VERSION "LiveWire S2 Del Mar (2024, S2DM) - Secondary CAN (DLC tap) - community reverse-engineered v0.1"
// [UPDATE 2026-07-27 — ride1 real-timestamp capture + deep review; double-verified.
//  0x181 IS THE FULL BMS MEASUREMENT FRAME: pack voltage + signed pack current.
//  RETRACTS the "~2.9-3 V/count", batt_flow_181, and the D3 "redundant-voltage" audit
//  below (every legacy observation re-explains as IR-drop on ONE voltage).]
//   pack_voltage = (D1:D2) >> 4 = 1 V/count (12-bit). Rest ~389 V @ 92% SoC; WOT dip
//     to 304 V then recover (ride1 393->304->393). D5 (pack_voltage_d5copy) is a
//     legacy 8-bit COPY = volts-256 (exact or off by <=2) - THIS is what the old
//     "~2.9-3 V/count" was mis-scaling; it is 1 V/count with a 256 offset.
//   pack_current = (D2&0x0F)<<12 | D3<<4 | D4>>4, then I = (raw-4000)/10 A, CHARGE-
//     POSITIVE. Zero-pinned: contactor-open raw=4000 (true 0 A) in 48/80 ignition
//     frames; DC-DC quiescent -0.2..-0.5 A at rest. WOT -189.5 A @ 304 V = 57.6 kW
//     (<63 kW rated). Charging +1.3..+3.9 A at 392-395 V ~ L1 wall power. D4 LOW
//     nibble = validity flag (0 co-occurs with raw==4000 in ~98-100% of open frames).
//   [CHARGE-POSITIVE RE-CONFIRMED 2026-07-28] The charge-positive sign is independently
//     re-confirmed by a sustained external charge (s32-s35: 100% positive pack_i with
//     monotonically rising V/SoC/cells), cross-checked vs UDS RESS 0209 pack current.
//   OHMIC CROSS-CHECK: V = 387.5 - 0.438*I, r=0.9947, rms 1.57 V, n=169 (~4.6 mohm/
//     cell at 96S); slope reproduces cross-capture. Independently cross-validated by
//     the 0x186 Wh meter integral (see 0x186). Continuous pack current/power IS on
//     secondary - RETRACTS the project's "pack current absent" gap.
//   ABSOLUTE 0.1 A/count rests on the wall-wattage match -> pin with an L2 (~5 kW)
//     charge (should read +12..13 A, raw ~4120-4130).
//   (D6 still 0x00 unused. The old counterexamples - "75mph"/manual-spin high current
//    at rest - resolve as unloaded STAND spins, ~-15 A at wheel inertia.)
// --- SUPERSEDED HISTORICAL DECODE (kept as the research record; do NOT wire) ------
// [STRONG] 0x181 D5 = PACK (HV BATTERY) VOLTAGE.
//   FOUND BY SYSTEMATIC TIMELINE CORRELATION (rider's suggestion): correlating every
//   raw byte against every confirmed signal across 6 dynamic captures surfaced
//   0x181 D5 at r=+0.80 vs battery flow - it had been sitting unexplained for the
//   whole project.
//   EVIDENCE IT IS VOLTAGE rather than another power field:
//     1. RESTING VALUE TRACKS SoC MONOTONICALLY across 47 captures:
//          SoC  96% -> 135       SoC  99% -> 136
//          SoC  97% -> 135/136   SoC 100% -> 137  (test.csv 138)
//          SoC  98% -> 135/136
//        Only an open-circuit voltage behaves like this - a power or current field
//        reads the same at rest regardless of SoC.
//     2. SAGS UNDER LOAD: falls to 127 during hard acceleration.
//     3. RISES WHEN CHARGING: 138-139 charging, 139 peak on regen.
//   SCALE: ~2.9-3 V PER COUNT, i.e. a ~400 V pack. RESOLVED BY PHYSICAL MEASUREMENT.
//     The rider measured the HV pack-to-inverter cable at 10 mm OD including
//     insulation. With typical HV wall thickness that implies roughly a 16 mm^2
//     conductor, good for ~110-150 A. At 63 kW peak that demands a HIGH-voltage
//     pack (~400 V, ~160 A). A 136 V pack would need ~460 A, requiring 50-70 mm^2
//     and a 15-20 mm OD - twice what was measured. So raw = volts is WRONG.
//     136 counts x ~2.9 V = ~394 V, which at ~96 series cells is 4.1 V/cell at full
//     charge - exactly as sensible as the 33s arithmetic below.
//   *** RETRACTED: "raw = volts, ~136 V pack, ~33s". The cell-voltage arithmetic
//     that supported it is WORTHLESS AS EVIDENCE because it works equally well for
//     BOTH hypotheses (33 cells at 1 V/count and 96 cells at ~2.9 V/count both give
//     ~4.1 V/cell). It only looked convincing because the alternative was never
//     checked. Lesson: internal consistency of a scaling assumption is not evidence
//     unless the competing assumption fails it.
//   *** ALSO RETRACTED: the "no DC fast charging implies a sub-threshold pack"
//     argument. At ~400 V the S2 is comfortably above any DCFC minimum, so the
//     omission is a cost / packaging / thermal decision, not physics.
//   REMAINING UNCERTAINTY: the exact counts-per-volt (2.9? 3.0?) is not pinned - the
//     cable gauge fixes the ORDER OF MAGNITUDE, not the precise scale.
//   DEFINITIVE TEST: a UDS read of the RESS returning pack voltage in known units.
// [STRONG] 0x181 D2:D3 (16-bit) = another battery flow / current-like channel.
//   r = +0.874 vs battery flow, -0.732 vs motor load. Rest 33017, charging 45307,
//   ride 241..61681. Bidirectional about rest with discharge swinging ~3x further
//   than regen, consistent with drive-vs-regen asymmetry. Resolution (30 distinct
//   values in a ride) is comparable to existing flow fields, not better - so it is
//   NOT the "true continuous" battery power still being sought.
// FULL FRAME MAP for 0x181 (audited byte by byte):
//   D1 = 23-24, essentially constant. Header / status. No information yet.
//   D2 = battery-flow-like, QUANTISED to multiples of 16 (0..240). r=+0.87 vs
//        battery flow, -0.73 vs motor load. Another stepped flow copy, not finer.
//   D3 = REDUNDANT PACK-VOLTAGE MEASUREMENT (hypothesis, well supported).
//        r=+0.977 vs D5, same 13 distinct values, band 236-252, same direction
//        (falls under load, rises charging), and sags by nearly the same ABSOLUTE
//        amount as D5 (6 vs 7 counts) - i.e. same scale.
//        KEY EVIDENCE: D3 - D5 is tightly clustered at 113 but NOT constant - it
//        spans 111..115 (113 = 51 %, 112 = 21 %, 114 = 17 %, 111 = 11 %). If D3 were
//        derived arithmetically from D5 the difference would be EXACTLY fixed. The
//        +/-2 count jitter means these are TWO INDEPENDENT MEASUREMENTS of the same
//        quantity, sharing a scale but using a different encoding offset.
//        WHY A SYSTEM WOULD DO THIS: safety-critical HV packs measure voltage on two
//        separate sense paths and cross-check them. Deliberately DIFFERENT offsets
//        mean a stuck bit or failed ADC cannot produce two matching plausible values
//        - any disagreement beyond a threshold flags a sensor fault. The +/-2 counts
//        is the expected noise between two ADC chains.
//        RULED OUT: D3 as MINIMUM CELL VOLTAGE. A weakest-cell reading must sag
//        proportionally HARDER than the pack under load; D3 sags 2.6 % against the
//        pack's 5.2 %, i.e. LESS. Not a cell-level metric.
//   D4 = shared STATUS byte (0xD1<->0xE1 tracks kickstand, but it also moves during
//        signal tests). Do NOT pair D3:D4 as a 16-bit value - although that pairing
//        correlates r=+0.985 with pack voltage and shows 77 distinct values, the
//        SPREAD WITHIN a single D5 step (up to 496) exceeds the step size (~238),
//        i.e. the extra "resolution" is D4's status bits leaking in, not real
//        precision. A tempting false lead.
//   D5 = PACK VOLTAGE (see above).
//   D6 = always 0x00 in every capture. Unused.
//   WHAT ITS CONSUMERS NEED (reasoning from the three secondary-bus receivers -
//   the IM/dash, the TCU/app, and the DLC - since the RESS itself is on primary,
//   everything gatewayed here serves a DISPLAY, an APP or a DIAGNOSTIC, never a
//   control loop):
//     satisfied here  -> pack voltage (the dash Diagnostics page shows voltages),
//                        battery flow (app power display), redundancy cross-check
//     satisfied elsewhere -> SoC (0x185), charge state (0x1A7), temps (0x183)
//     STILL UNLOCATED, and worth hunting because a dash/app plausibly needs them:
//       * BATTERY WARNING / FAULT flags (over-voltage, under-voltage, over-temp).
//         Likely a bitfield; look for a byte that is 0 in all healthy captures.
//       * STATE OF HEALTH (SoH). Would be near-constant across every capture and
//         change only over months - effectively invisible in this dataset. A byte
//         sitting at a fixed high value (e.g. ~100, ~200, ~255) is a candidate.
//       * AVAILABLE POWER LIMIT (discharge/charge ceilings the BMS computes from
//         SoC and temperature). Would move with temperature and SoC but NOT with
//         instantaneous load - a distinctive signature worth testing when the pack
//         is cold vs hot.
//       * TIME-TO-FULL while charging - would count DOWN during a charge session.
//   CONCLUSION: this frame contains NO continuous absolute power value. Its flow
//   channels (D2) are stepped like all the others.
// ---- 0x260 (608) : mode mirror ----------------------------------------------
BO_ 608 MODE_MIRROR_260: 8 Vector__XXX
 SG_ ride_mode_mirror : 7|8@0+ (1,0) [0|255] "" Vector__XXX
 SG_ ride_mode_mirror_d2 : 15|8@0+ (1,0) [0|255] "" Vector__XXX

// [CONFIRMED] 0x260 D1 mirrors 0x134 D1 ride-mode enum exactly
//   (22->88->99->33->44->11->22 through the mode cycle).
// [CONFIRMED] 0x260 D2 high-nibble = mode id too (20/10/40/30/80/90 for
//   Sport/Street/Eco/Rain/CustA/CustB); low nibble 0. See the 0x134 mode table.
// ---- 0x562 (1378) : ODOMETER ------------------------------------------------
BO_ 1378 ODOMETER_562: 8 IM
 SG_ odometer_m : 15|24@0+ (1,0) [0|16777215] "m" Vector__XXX
 SG_ msg_counter_562 : 55|8@0+ (1,0) [0|63] "" Vector__XXX

// [CONFIRMED] 0x562 D2:D3:D4 (24-bit big-endian) = odometer in METERS.
//   0x3DA4B5 = 4039861 m = 4039.86 km = 2510.26 mi  vs dash 2510 mi. Exact.
//   Verified again on 75mph run: 4039947m (2510.31mi) start, accumulated with
//   wheel travel. 0x3C6 D2:D3:D4 mirrors the same odometer (D6=0x30 constant).
//   D7 = rolling counter (0-63), D8 = checksum (ignore).
//   [UPDATE 2026-07-27] Confirmed with real timestamps: 0x3C6 D2:D3:D4 is an
//   unprotected ECHO of this odometer, lagging a median 214 ms (0/69 leads). This
//   DISSOLVES the ride1 "0x3C6 D4 ramp 0x61->0x71" candidate - it is just the
//   odometer low byte advancing. (0x562 itself integrates the REAR/motor-derived
//   speed: it over-counts under wheelspin and advances during stand spins - +223 m
//   logged in the 75mph stand capture with the front wheel static.)
// ---- 0x354 (852) : left switchgear - horn + info/scroll button --------------
BO_ 852 LEFT_SWITCH_354: 8 BCM
 SG_ horn : 15|8@0+ (1,0) [0|255] "" Vector__XXX
 SG_ info_scroll_button : 7|8@0+ (1,0) [0|255] "" Vector__XXX

// [STRONG] 0x354 D1 = dash INFO / SCROLL button (left cluster): 0x00 released,
//   0x01 pressed. Isolated in tripA71to0tripB70p9to0: pulsed ~3x while navigating the
//   dash menu to reset Trip A then Trip B. It is 0x00 with ZERO changes in every
//   control capture (idle, cyclemodes, highbeam, AND horn3x - where D2/horn pulses but
//   D1 stays flat), so it is a distinct button, not horn bleed. Same frame as the
//   horn = left switchgear. Exact button label (info vs mode) is [STRONG] not proven,
//   but it is the dash-navigation button used for trip reset / display cycling.
// [CONFIRMED] 0x354 D2 = horn: 0x00 released -> 0x01 pressed.
//   Verified with horn3x_fast capture: pulses EXACTLY 3x matching 3 honks, AND
//   reads 0x00 in every non-horn capture (idle, ignition, highbeam, turn signal).
//   NOTE: a single 1s press was inconclusive (one pulse indistinguishable from
//   idle jitter; several noise bytes looked like false candidates). The 3x-fast
//   capture was required to isolate it - the repeating 3-pulse signature plus
//   cross-check against non-horn captures eliminated all impostors.
//   (Earlier tentative "horn = analog" conclusion was WRONG - corrected here.)
// ---- 0x326 (806) : PER-WHEEL SPEEDS (front + rear, ABS sensors) -------------
BO_ 806 WHEEL_SPEEDS_326: 8 Vector__XXX
 SG_ wheel_speed_front : 7|16@0+ (0.1,0) [0|6553.5] "km/h" Vector__XXX
 SG_ wheel_speed_rear  : 23|16@0+ (0.1,0) [0|6553.5] "km/h" Vector__XXX

// [CONFIRMED] 0x326 D1:D2 = FRONT wheel speed, D3:D4 = REAR wheel speed.
//   Both 16-bit big-endian, same scale as vehicle_speed (km/h x10). Rest/zero
//   value is 2 (not 0) for both.
//   ISOLATION (definitive - the two halves of the dataset):
//     FRONT-only hand spin  -> D1:D2 = 2..48 ALIVE,  D3:D4 = 2 static
//     ALL rear-only spins   -> D1:D2 = 2 static,     D3:D4 tracks motion
//     idle (neither moving) -> both = 2
//   Scale cross-check vs 0x160 vehicle_speed: rear D3:D4 = 160 when speed = 161
//   (10 mph run) and 1245 vs 1248 (75 mph run). Same units.
//   NOTE: every capture before frontspin_5s had the front wheel STATIONARY, which
//   is why D1:D2 looked like a dead byte until the dedicated front-spin capture.
//   [CONFIRMED] FRONT wheel speed is UNSIGNED - spinning the front wheel BACKWARD
//   produces the same positive magnitude as forward (min value never drops below
//   the rest value of 2), and NO byte anywhere on the bus distinguished front
//   rotation direction. Only the MOTOR (0x160 D3:D4, offset 1000) is signed.
//   Verified with frontwheel_forward_back_5sgap.
// [UDS CROSS-REF 2026-07-28] EHCU UDS DID 020F mirrors this frame: u16@0 = FRONT, u16@2 =
//   REAR, ~25x these raw counts (~250 counts/km/h, ~0.004 km/h/count), 0/0 at standstill,
//   r=1.000 (streamed rides s28/s31). REAR leads FRONT by +256 quanta under power (mild
//   TC-active slip). See the UDS-DERIVED CALIBRATION block (EHCU ABS BLOCKS entry).
// ---- 0x322 (802) : drivetrain / motion state -------------------------------
BO_ 802 DRIVE_STATE_322: 8 Vector__XXX
 SG_ power_state  : 7|8@0+ (1,0) [0|255] "" Vector__XXX
 SG_ yaw_rate_coarse : 7|8@0+ (1,-111) [-20|24] "coarse yaw (~x0.0018 of 0x126)" Vector__XXX
 SG_ motion_state : 23|8@0+ (1,0) [0|255] "" Vector__XXX
 SG_ roll_angle_integral_322 : 15|8@0+ (1,0) [0|255] "" Vector__XXX

// [NOTE] power_state and yaw_rate_coarse are the SAME 8 bits (D1, 7|8@0) BY DESIGN - a
//   dual-view, not a duplicate-signal error: power_state reads D1 as the 0xFF=off / ~0x6F=on
//   power byte, yaw_rate_coarse reads the same byte as the live coarse yaw around the 0x6F zero.
// *** [SUSPECT 2026-07-27 — deep review] The D3 motion_state enum + rear-brake bins
//   below are DOWNGRADED from CONFIRMED. ride1 (real timestamps) shows D3 is a smooth
//   session-dependent wrapping integrator: the SAME physical state reads 2-3 in one
//   session and 21-22 in another (rest value not power-cycle-stable), advancing +/-1-2
//   per frame with clean mod-256 wraps - not a small fixed enum. The survey lane's
//   competing read (D1 yaw-tracking r=+0.93, D2hi wrapped roll-integral r=+0.96, D3
//   heading-like) is UNVERIFIED (single dynamic capture). Do NOT wire motion_state or
//   the brake bins until a figure-8 / weave capture settles it. The 0x14/15/17 values
//   below were real observations but likely a coincidental slice of the integrator. ***
//   [PROMOTED 2026-07-30, ultracode - multi-capture, supersedes the "single dynamic" caveat]
//     D2 (roll_angle_integral_322) is CONFIRMED a mod-256 wrapping roll/lean integrator, NOT a
//     discrete state: under ride it cycles EVENLY through all 16 hi-nibble values (s54/s55/s57
//     ~equal count per nibble); a deliberate hand-rock lean session sweeps all 16; idle collapses
//     to nibbles 5-6. This also kills the stray "0x322 D2 = contactor state" hypothesis (a
//     contactor cannot cycle uniformly through 16 values). D3 motion_state stays SUSPECT.
// [CONFIRMED->SUSPECT] 0x322 D3 = motion / brake state:
//     0x14 = stopped (ignition on, enabling, ready-but-stationary)
//     0x15 = ROLLING
//     0x17 = BRAKING  (observed exactly during the rear-brake stop)
//   Anchored using the confirmed rear-brake signal (0x133 D4) in the same capture.
//   ALSO ENCODES A COARSE REAR-BRAKE-FORCE LEVEL (rearbrake_3xlight_3xHARD, bike
//   stationary, motor off): baseline 0x02/0x03, and it CLIMBS with hard rear
//   braking - reaching 0x05, 0x06, 0x07 on three successively harder presses, then
//   dropping back to baseline between presses. The 3 LIGHT presses did not move it
//   (stayed 0x02/0x03). So D3 is a low-resolution brake/deceleration-demand level,
//   NOT a pressure reading - and it responds only above a firm-pressure threshold.
//   *** BLIND-TEST VALIDATED + LIMITS FOUND (brakes_verification.csv, script
//   Rl,Rl,Rm,Rh) ***: of 4 rear presses, only 3 tripped 0x133 D4; one LIGHT press
//   left ZERO trace (below threshold) - confirming the no-rear-sensor model. AND D3
//   SATURATES at 0x06: the medium and hard presses both peaked at 0x06,
//   indistinguishable, while the light-but-tripped press held D3=0x03. So the rear
//   brake resolves to only THREE crude bins - firm (D3~6) / just-tripped (D3~3) /
//   invisible (no trip) - and CANNOT be read as a graded force. Do not treat D3 as a
//   pressure value. (Front 0x324, by contrast, is a true continuous analog.)
// [CONFIRMED] 0x322 D1 = power/awake: 0xFF when system OFF, ~0x6F when powered.
// *** [PROMOTED 2026-07-28 — streamed rides s28/s31/s44] D1 is NOT a constant 0x6F while
//   powered: 0x6F(111) is the yaw ZERO-point, and D1 swings +/-~22 counts around it as a
//   COARSE SIGNED YAW-RATE byte (the VSC/ABS module's own published yaw, an 8-bit copy of
//   the 16-bit 0x126 gyro_yaw). Evidence over 3 moving sessions: r(D1,0x126 gyro_yaw) =
//   +0.81 (s28, n=22146) / +0.87 (s31, n=5956) / +0.84 (s44, n=15659) / +0.85 (s55 NEW,
//   n=25022); rest value (speed=0, |yaw|<80) = 109.5 / 111.7 / 111.9 / 112.1 ~= 0x6E-0x70;
//   r(D1,speed)~=0 and r(D1,acc_lat)
//   only -0.55..-0.62 (yaw dominates lean) -> it is yaw RATE, not lean or speed. Sign: +yaw
//   -> higher D1 (s44 yaw +10415 -> D1=0x80; yaw -8765 -> D1=0x62). Range 91-135 (clips at
//   large yaw = coarse). This satisfies the SUSPECT block's "do not wire until a figure-8
//   capture" caveat (now 4 independent rides: s28/s31/s44 + s55). Wired as yaw_rate_coarse
//   (offset 111). D1 only
//   read constant 0x6F before because every prior capture was stationary/bench ("constant
//   != understood"). D2 (roll) / D3 (heading) remain OPEN — D3-as-heading was REFUTED (dD3
//   /dt vs gyro_yaw r~=0 in all 3 sessions).
// [RETRACTED 2026-07-29 — was "[STRONG] 0x322 D2 = 0xFF off, 0xE7 powered, 0xF7 during/after
//   shutdown"] D2 is NOT a static power-state byte: 0xE7 was one static phase seen on bench/parked
//   captures. 0x322 D2 = ROLL / LEAN-ANGLE INTEGRATOR (roll_angle_integral_322) = a mod-256 wrapping
//   integral of roll RATE = the EHCU/MSC lean/roll-angle estimate. d(D2)/dt vs 0x126 gyro_roll
//   r = +0.575..+0.704 over 4 rides (same using only the smooth high nibble -> the correlation is in
//   the integrator, not the LSB dither); ~=0 vs yaw/pitch/speed/pack-current. Ramps up/down while
//   moving, dithers narrowly at rest. Directly parallels how 0x322 D1 was promoted from constant-0x6F
//   to coarse yaw. CAVEAT: wraps mod-256, NOT power-cycle-stable -> a module-internal integrator, not
//   a calibrated-degrees channel (scale open). This RESOLVES the "D2 (roll) remains OPEN" note above
//   and confirms the survey lane's D2hi roll-integral read (r=+0.96, 4 rides now). DT-II: Bosch MSC
//   estimates lean angle. [STRONG attribution; scale open.]
//   (Old note preserved: earlier speculation guessed the D2 high-nibble was a contactor sequence;
//   the full sequence capture showed D2 steady while POWERED - that "power-state" read is now
//   superseded by the roll integrator, which the bench/parked captures simply could not exercise.)
// ---- 0x324 (804) : FRONT BRAKE PRESSURE (analog) ----------------------------
BO_ 804 FRONT_BRAKE_PRESSURE_324: 8 Vector__XXX
 SG_ front_brake_pressure : 7|16@0+ (1,0) [0|65535] "raw" Vector__XXX

// [CONFIRMED] 0x324 D1:D2 (16-bit big-endian) = FRONT brake lever PRESSURE (analog).
//   0 = released; rises PROPORTIONALLY with lever force. Found in
//   various_brake_pressures.csv: per-press PEAK climbed with squeeze intensity -
//     press1 (feather) 329 -> 2470 -> 2612 -> 3111 -> 3298 -> 3395 (hard)
//   and WITHIN a single press it ramps smoothly (D2 0B,15,1D,29,40,49,53,62,75...).
//   FRONT-SPECIFIC + ZERO BASELINE (definitive isolation):
//     - idle, no brake: 0 in EVERY frame (idle_97percent, idle_92f).
//     - brakelight_front_rear capture: FRONT-only press -> rises (max 1151);
//       REAR-only press (0x133 D4) -> stays 0; neither -> 0. Tracks the FRONT lever
//       ONLY, so it is not a combined or rear signal.
//   *** RESOLVES THE 3-WIRE FRONT-BRAKE SWITCH ***: the third wire is an ANALOG
//   PRESSURE output (Vcc / GND / signal). Unlike throttle POSITION - which the RHCM
//   keeps on primary, gatewaying only a binary "throttle not zero" - this analog
//   brake pressure IS broadcast on secondary. It sits in the chassis/ABS ID cluster
//   (0x322 drive-state, 0x326 wheel speeds), so it is plausibly published by the
//   ABS/EHCU or a chassis module (regen-blend / ABS input). The binary front-brake
//   indicators 0x15A D1 (0x10/0x01) and D6 (0x00/0x40) are SEPARATE derived on/off
//   states - they trip together across all pressures (no two-stage), so the "two
//   channels" are redundant switch reads, distinct from this analog line.
//   UNITS UNKNOWN: raw spans 0..~3400 at a hard press - looks like ADC counts
//   (possibly ~12-bit). Proportional/relative reading is solid; absolute units
//   (kPa/psi) need a reference pressure gauge on the line.
//   OTHER BYTES: D5 toggles 0x51/0x92 (mux or 1-bit counter), D7 = rolling counter,
//   D8 = checksum, D3/D4/D6 constant 0x00/0x00/0x3A.
//   HISTORY: 0x324 previously appeared only in the boot-wake list (0xFF->real) and
//   was never decoded. It reads 0x0000 in nearly every capture because almost none
//   involved a stationary front-brake pull - the dedicated pressure sweep exposed it.
//
// *** REAR BRAKE HAS NO EQUIVALENT ANALOG PRESSURE CHANNEL - and the hardware
//   explains why. *** The rider confirmed the REAR master cylinder has NO WIRES on
//   it (front has the 3-wire sensor; rear has none). So there is no electrical
//   pressure sensor at the rear pedal - rear application is sensed HYDRAULICALLY
//   inside the ABS unit (EHCU), which has its own line-pressure transducer.
//   Consequence on secondary (rearbrake_3xlight_3xHARD, 3 light then 3 hard presses):
//     - NO smooth 16-bit analog channel appears anywhere (searched all bytes).
//     - 0x133 D4 (rear "switch") is THRESHOLD-based: 0x00 for all 3 LIGHT presses,
//       0x10 only for the 3 HARD ones - i.e. it needs enough line pressure to trip,
//       consistent with a pressure switch in the hydraulics, not a pedal microswitch.
//     - 0x322 D3 climbs 0x02/03 -> up to 0x07 on hard presses only (coarse ABS
//       brake-force level, see that frame).
//     - The 3 LIGHT presses produced ZERO bus activity of any kind.
//   Red herrings ruled out: 0x33C and 0x3CE flip A/B on a fixed ~4.9% period
//   regardless of braking (periodic heartbeat/mux frames), and 0x3C4 D3 is a rolling
//   counter (higher on hard presses only because they occur later in the capture).
//   NET: front brake pressure is a real gatewayed analog (0x324); rear brake exposes
//   only a threshold switch + a coarse ABS state - no rear pressure value on secondary.
// ---- 0x500-0x516 : boot / ready / power state flags -------------------------
// [STRONG] All single D1 booleans (0x00/0x01), DLC 1. Decoded against the full
//   ignition -> boot -> ready -> enable -> ride -> disable -> off sequence.
//   [ROUND-4 2026-07-28] Confirmed as ORDERED per-subsystem enable bits: they rise
//   0->1 in a fixed boot ORDER (0x501 leads) and fall / re-toggle at disable events
//   (0x504/0x505 re-toggle on disable). The per-ID subsystem mapping below stands; the
//   ordering is the new structural fact (a boot-sequence, not independent flags).
//   BOOT SEQUENCE observed (percentages of that capture):
//      0.1%  ignition on (0x133 D1 0x20->0x60)
//      2.5%  bulk module wake - 0x122/0x124/0x126/0x128/0x322/0x324/0x326 all
//            transition from 0xFF (asleep/invalid) to real values
//     12.0%  0x516 clears 01->00
//     12.4%  0x503 clears
//     12.6%  0x507 clears
//     14.8%  0x505 clears
//     15.2%  0x504 clears
//     20.1%  0x3C6 odometer data becomes valid  => SYSTEM READY TO ENABLE
//     33.3%  START pressed (0x133 D1 0x60->0x80)
//   FLAG MEANINGS (revised - supersedes the earlier vaguer grouping):
//     0x516, 0x503, 0x507 = INIT/self-test flags. 0x01 during boot, clear once
//        that subsystem finishes initialising, never return. Clear order is
//        repeatable and is a usable "boot progress" indicator.
//     0x504 = 0x01 during boot, 0x00 when idle-ready, then 0x01 again at 34.5%
//        i.e. IMMEDIATELY after the motor is enabled => tracks MOTOR/INVERTER
//        ACTIVE (active during init and while enabled, idle in between).
//     0x505 = INVERSE READY flag. Clears at 14.8% and stays 0x00 for the entire
//        ready+riding window, returns to 0x01 at 83.9% exactly when the motor is
//        disabled. So 0x00 = system ready/operational, 0x01 = not ready.
//     0x500, 0x515 = SYSTEM POWER. 0x01 while powered, clear at 87.1%/87.4%
//        when ignition goes off.
//     0x50A = final SHUTDOWN/sleep flag, clears last at 97.9%.
//     0x501, 0x506 = always 0x01 in every capture so far (no information yet).
//   NOTE: the rider confirmed the system takes a long time to become ready and
//   that there is a deliberate ~5 s idle AFTER ready before pressing START -
//   that idle is the 20%..33% window above, which is why "ready" and "enable"
//   are cleanly separable in this capture.
// ---- 0x392 (914) : TCU CELLULAR / NETWORK STATUS [frame+state CONFIRMED] ----
BO_ 914 TCU_NETWORK_392: 8 TCU
 SG_ tcu_signal_candidate : 7|8@0+ (1,0) [0|255] "" Vector__XXX
 SG_ tcu_operator_id : 15|24@0+ (1,0) [0|16777215] "" Vector__XXX

// [CONFIRMED 2026-07-28] D1 REGISTRATION STATE moves in lockstep with the operator
//   field: D1=0x00 <-> operator collapses to 00 00 01 = modem NOT registered; D1 in
//   {1A,1B,1C} <-> operator = <operator-id-redacted> = registered on the home network. Verified across
//   startup (both states in one capture), ride, and charge. So D1 is a combined
//   registration+signal byte; the exact RSSI grading WITHIN {1A,1B,1C} is still unpinned
//   (no mid-bar sample logged). tcu_operator_id <operator-id-redacted> = carrier id (NOT a raw PLMN;
//   UDS ground truth is Verizon MCC<redacted>/MNC<redacted> = <home-PLMN-BCD-redacted>, which does not match - see below).
// [BURST UPDATE 2026-07-28] The SERVING PLMN (UDS TCU DID 0296) SWITCHED Verizon(<home-PLMN-redacted>) ->
//   T-Mobile(310/260) during the streamed burst, yet broadcast operator_id stayed <operator-id-redacted>
//   across s28/s31/s32/s35 -> LIVE proof that operator_id = SIM HOME-network id, NOT the
//   serving PLMN. Registered D1 set EXTENDED {1A,1B,1C} -> {1A,1B,1C,1D} (0x1D = the burst
//   registered value). The s26 not-registered blip (D1=00, operator 00 00 01) is coincident
//   with UDS 0296='  0  0' searching -> the D1 registration byte is cross-corroborated by 0296.
// [TENTATIVE 2026-07-27b] *** RETRACTS the earlier "0x392 = boot config" note. ***
//   This is the TCU's own broadcast frame - proof the TCU IS a secondary producer
//   (the dash shows cellular signal strength, so by the architecture rule it must be
//   gatewayed, and here it is). TWO STATES across 57 captures:
//     REGISTERED      : D1=1A/1B/1C  D2:D3:D4 = <operator-id-redacted>   (carrier/network id, see below)
//     NOT-REGISTERED  : D1=00     D2:D3:D4 = 00 00 01
//   Transitions LIVE: startup_nofob drops 1B <operator-id-redacted> -> 00 00 00 01; ride3 sits
//   unregistered its whole 38 s (modem had not connected after power-on-then-ride).
//   tcu_signal_candidate (D1) is the SIGNAL-STRENGTH candidate but UNCONFIRMED: across
//   all captures D1 is only ever {0, 26, 27, 28} = disconnected or strong - there is NO
//   mid-signal sample (every capture was in good signal; rider has SEEN 2->5 bars in
//   the garage but we never logged a low-bar moment).
//   tcu_operator_id (D2:D3:D4) = CARRIER / NETWORK (PLMN-like) identity, NOT a serving
//   cell/tower [UPDATE 2026-07-27b]: <operator-id-redacted> in ALL 48 registered captures, which span
//   a 15 km odometer range (4039.74 -> 4054.72 km = many sessions/locations, well beyond
//   single-tower spacing). A tower/cell id would have changed repeatedly over that
//   distance; this never did => it tracks the SIM's home network, not the cell. (Only a
//   capture from a genuinely distant area - a different town, tens of km - could still
//   flip it and would be the definitive tower-vs-carrier test.)
//   DEFINITIVE TEST: log in the garage while the dash bars change (they wander 2-5),
//   note the timestamp of each change; the byte that steps with the bars is signal
//   strength (may be D1 or a companion). Zero risk. Until then, treat the connected/
//   not-connected STATE as solid and the exact D1 meaning as a hypothesis.
//   [PLMN CRACK 2026-07-27, attempted -> NEGATIVE] UDS ground truth from the TCU (0x7D4)
//   is Cubic Telecom eSIM on Verizon, PLMN MCC <redacted> / MNC <redacted>. The standard 3-octet BCD
//   PLMN encoding of <home-PLMN-redacted> is 13 F1 84 (nibble-swapped), which does NOT match <operator-id-redacted>
//   in any octet order or endianness. So D2:D3:D4 is a carrier/network identity in some
//   OEM/modem-internal representation, NOT a raw 3GPP PLMN - question "is it a PLMN?"
//   is answered (no). The carrier itself is known from UDS; this frame need not decode it.
//   [PLMN-CRACK CAVEAT 2026-07-28] UDS DID 0296 is the SERVING PLMN and it has since switched
//   to T-Mobile 310/260, while operator_id <operator-id-redacted> stayed fixed -> 0296 is NOT valid ground
//   truth for <operator-id-redacted> (which encodes the SIM HOME network). Any crack must target the SIM
//   home PLMN (<home-PLMN-redacted> Verizon), NOT the now-changed serving 0296 value.
//   (GPS position was NOT found on secondary - the telematics cluster stays frozen
//   through a moving ride; it is TCU-local or UDS-only.)
// ---- 0x124 (292) : fused / mean wheel speed --------------------------------
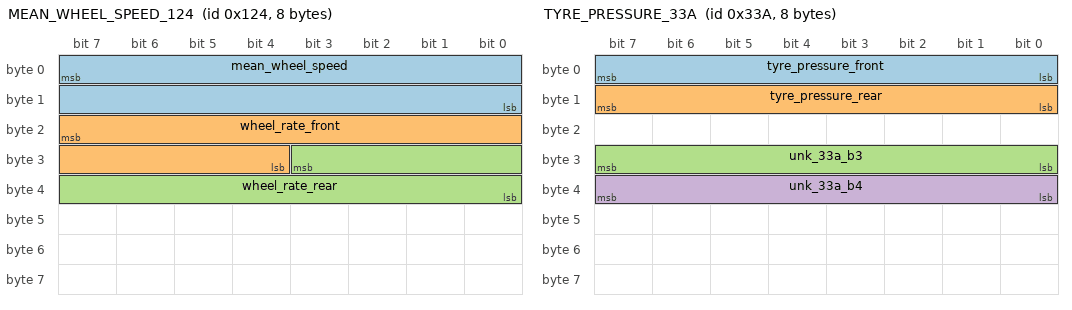
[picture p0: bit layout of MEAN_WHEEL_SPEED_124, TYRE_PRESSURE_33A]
BO_ 292 MEAN_WHEEL_SPEED_124: 8 Vector__XXX
 SG_ mean_wheel_speed : 7|16@0+ (0.1,0) [0|6553.5] "km/h" Vector__XXX
 SG_ wheel_rate_front : 23|12@0+ (0.12195,0) [0|499] "km/h" Vector__XXX
 SG_ wheel_rate_rear : 27|12@0+ (0.1255,0) [0|514] "km/h" Vector__XXX

// [UPDATE 2026-07-27 — ride1 real-timestamp capture + deep review; double-verified.
//  0x124 D3/D4/D5 = TWO PER-WHEEL 12-BIT WHEEL RATES (unifies + replaces the D5
//  "0.795x rear" partial below).]
//   wheel_rate_front = (D3<<4)|(D4>>4)   -- FRONT, 0.820 counts per 0.1 km/h
//   wheel_rate_rear  = ((D4&0x0F)<<8)|D5 -- REAR,  0.797 counts per 0.1 km/h
//   (wheel RPM; per-wheel rolling circumference ~2.03/2.09 m -> the km/h SCALE is
//   inferential, not pinned.) ride1 vs 0x326: front r=0.99959, rear r=0.99920;
//   independence proven (cross-wheel r=-0.36; during the slip own-wheel error
//   7.3/20.3 counts vs cross-wheel 118/127). *** This DISSOLVES the ride1 "0x124 D4
//   low nibble 1->2 at 15.35 s" TC candidate: it is wheel_rate_rear crossing 512
//   (=64.3 km/h), a 12-bit carry with D5 wrapping the same frame - NOT a flag.
//   mean_wheel_speed (D1:D2) is unchanged and still valid.
// --- SUPERSEDED: the D5 "rear_derived 0.795x" partial is the low 8 bits of
//     wheel_rate_rear; the 0.795 factor was that truncation. Kept for provenance. ---
// [CONFIRMED] 0x124 D1:D2 (big-endian) = MEAN of the two wheel speeds:
//     0x124 D1:D2  ==  ( 0x326_front + 0x326_rear ) / 2
//   Same units as the individual wheel speeds (km/h x10), rest value 2.
//   DEFINITIVE TEST: with BOTH wheels hand-spun at DIFFERENT rates
//   (bothwheels_manualspin_forward_3x), mean |error| vs the average was
//   0.50 counts (i.e. rounding) versus 3.1-4.0 counts for every alternative
//   (front-only, rear-only, max, min). Averaging wins decisively.
//   This also explains the long-standing puzzle that 0x124 D1:D2 read EXACTLY
//   0.50 x vehicle_speed in every rear-only capture: with the front wheel at
//   rest, (front + rear)/2 = rear/2. It was never a "half-scale speed" - it was
//   an average with one input pinned at zero.
//   INDEPENDENTLY RE-VALIDATED at EXTREME mismatch (front ~10 km/h vs rear ~35
//   km/h, and front ~100 vs rear at rest): mean |error| 0.70 counts versus 43+
//   counts for front-only or rear-only. The averaging relation holds across the
//   full mismatch range, not just small differences.
// [STRONG] 0x124 D5 = REAR-derived at 0.795 x rear wheel speed (matches every
//   sample within 1 count: rear 28->22, 25->20, 34->27, 32->25, 29->23, 26->21).
//   Stays at rest during FRONT-only spin => rear-sourced. The 0.795 scale on a
//   km/h x10 value implies ~7.95 counts per km/h, consistent with a rear WHEEL
//   RPM using a ~2.1 m rolling circumference. Not fully pinned.
//   NOTE: 0x124 D4:D5 is NOT a 16-bit pair (combining them yields nonsense);
//   D4 is a separate status/counter byte.
// ---- 0x184 (388) : 0x18x mux/counter cluster - NOT USB (retracted) ----------
// *** RETRACTED: "0x184 D5 = USB / accessory-port state". IT IS NOT. ***
//   A one-capture correlation (usbport_unplug_3x: D5 toggled 0x20<->0x30; six
//   controls sat at 0x30) LOOKED clean but was spurious. The definitive test
//   (quadlock_unplug_iphoneplug_iphoneunplug_quadlockplug_phoneonquadlock) contains
//   FIVE explicit connect/disconnect events - quadlock out, iPhone in, iPhone out,
//   quadlock in, phone-on-quadlock - and 0x184 D5 stayed CONSTANT 0x20 across all
//   360 frames. A real USB-state bit would have toggled >=4 times. It did not.
//   WHY THE CONTROL TEST FOOLED ME: 0x184 is part of the multiplexed 0x18x cluster.
//   Its D1/D2 vary BETWEEN captures (idle_97 = 1B A0.., cyclemodes = 1A C0..,
//   both USB caps = 1B F0..) and D5's 0x20/0x30 value rides with that mux/counter
//   state, not with the port. Looking at D5 in isolation, the controls happened to
//   sit at 0x30 - coincidence, not causation. Also: both USB captures STARTED
//   PLUGGED with D5=0x20, while the (also-plugged) controls read 0x30, so "plugged"
//   maps to BOTH values - impossible for a genuine state bit.
//   CONCLUSION: the front USB / accessory port is NOT represented on secondary CAN.
//   Confirmed across THREE captures: (1) usbport_unplug_3x (quadlock, no load) - the
//   0x184 D5 red herring; (2) the 5-event quadlock/iPhone test - 0x184 D5 flat, no
//   response, no new IDs (no TCU/infotainment wake for the data-capable iPhone);
//   (3) usb_wattmeter_7w - a MEASURED 7 W load (~0.58 A @ 12 V) plugged then
//   unplugged, and STILL nothing moved: aux voltage flat (0x332 D6 = 14.0-14.1 V),
//   0x184 D5 constant 0x20, no event byte, no new ID. Presence, LOAD (even 7 W) and
//   data are all absent. The port is a dumb tap off the DC-DC accessory rail with no
//   sensing gatewayed here; the DC-DC regulates 7 W away below the 0.1 V aux
//   resolution, and there is no accessory-current channel on secondary.
//   LESSON: a single capture's correlation - especially a lone byte inside a known
//   multiplexed frame - is a HYPOTHESIS, not a finding. It needs a second,
//   independent capture engineered to break it. This one did. (Do not re-add without
//   a capture where D5 tracks connect/disconnect edge-for-edge.)
// ---- 0x395 (917) : ABS/TC WARNING-LAMP SEARCH (negative result) -------------
//   The SINGLE BO_ 917 definition for 0x395 is TCU_PAIRING_395, further below - 0x395 is the TCU
//   cloud-link + cellular-signal frame. The former duplicate here ("BO_ 917 ROTATION_LATCH_395 /
//   SG_ rotation_latch : 39|8@0+" on D5) was REMOVED 2026-07-29 to dedupe the message id (two
//   BO_ 917 defs are invalid) AND because its decode is retracted:
// [RETRACTED 2026-07-29 — was "[STRONG] 0x395 D5 high nibble latches 0x1_->0x4_ ONCE at the first
//   wheel rotation = a rotation-sensed latch"]: D5 hi-nibble is NOT a one-shot latch - it sweeps
//   2..6 while moving (= the cellular SIGNAL-STRENGTH bars; see cellular_signal_395 on
//   TCU_PAIRING_395 below). The single-legacy-capture "latch" was a parked->moving signal change
//   misread as a latch. For the TC-disable state use 0x134 D2 low-nibble, not this.
//
// ABS/TC WARNING LAMP STATE: NOT FOUND on secondary CAN (searched exhaustively)
//   Rider lamp model:
//     BLINKING = self-test/init incomplete
//     SOLID    = rider manually disabled TC   -> this half IS known:
//                0x134 D2 LOW NIBBLE (3 = TC on, 9 = TC off), verified with a
//                dedicated TC-on->TC-off toggle capture at idle.
//     OFF      = active
//   Rider ground truth: self-test does NOT complete on first rotation. It needed
//   sustained fast FRONT spinning plus THROTTLE-driven REAR rotation; the lamps
//   latched out during that phase (~56-68% of tcabs_preinit_spin_warningoff).
//   SEARCHES PERFORMED on that window, all negative:
//     - whole-byte value-set changes  -> only counters / odometer
//     - oscillating-then-static (blink) patterns -> only 0x181 D2, which shows no
//       transition when checked over time
//     - BITWISE per-bit set/clear across the latch window -> 4 hits, all counters
//       (0x186 D2, 0x3C4 D2) or odometer low byte (0x3C6/0x562 D4 bit6)
//   The comparison was done WITHIN one capture (same ride mode, same lighting,
//   lamps-on early vs lamps-off late), so it is confound-free - and still nothing.
//   CONCLUSION: the cluster (IM) most likely DERIVES the ABS/TC telltale itself
//   (e.g. from validity/absence of a gatewayed EHCU status message) rather than
//   receiving an explicit lamp bit. Do not expect a simple lamp flag here.
//   NOTE: 0x3C4 D2 and D3 are ROLLING COUNTERS (D3 steps 19,1A,1B... 36,37,38) -
//   this also independently confirms the earlier retraction of the 0x3C4 D2
//   "turn intent" decode.
// ---- 0x3C8 (968) : EHCU / ABS-STABILITY STATUS -----------------------------
BO_ 968 ABS_STATUS_3C8: 8 Vector__XXX
 SG_ rear_abs_disabled : 31|1@0+ (1,0) [0|1] "" Vector__XXX

// [CANDIDATE 2026-07-29] D3 = 0xFF (all bits) latched under the dash "triangle-!" warning (s60) vs
//   0x3F/0xDF normal - fits the "D3 scrambles in fault" note below; part of the ABS/TC warning-icon
//   fingerprint (see the 0x128 note).
// [CONFIRMED - NEW, cracks a previously-unresolved frame] 0x3C8 is a PROTECTED
//   chassis-status frame (D7 = 6-bit alive counter 0..3F, D8 = CRC-8/J1850 - the same
//   Bosch EHCU (stability/ABS unit). Structure: D1=0x04, D2=0x24, D5=0x10 post-init
//   header. [CONFIRMED 2026-07-28] these three are 0x00 during the boot/self-test window
//   and FLIP TOGETHER (D1 00->04, D2 00->24, D5 00->10) at init completion = an ABS
//   init->ready handshake (D4=0x0F is the self-test code in that same pre-ready window).
//   D3 = a rolling status/validity bitfield (mostly 0x3F, F-heavy; state-linked: stand 8F
//   / motion 3F / charge FF, scrambles in the brownout fault - PLAUSIBLE stability+sensor-
//   validity word, see speculation doc, NOT yet a hard decode);
//   [CONFLICT 2026-07-29] a fresh module-lens pass reads rest=0x3F / motion=0xF_ - the OPPOSITE
//   rest/motion assignment to the "stand 8F / motion 3F" above - so the per-bit semantic stays
//   UNRESOLVED (very low ~0.6 Hz frame count; D8 CRC still verifies byte alignment). Keep as
//   candidate, not wired.
//   D6=0x00; D7 counter; D8 CRC.
//   *** D4 = ABS STATUS byte. D4 bit7 (0x80) = REAR ABS DISABLED. ***
//   Evidence: across ALL captures D4 is 0x00 in normal running and 0x0F only during
//   the power-up self-test (ignition/startup captures) - i.e. an init/not-ready code.
//   CORROBORATED across TWO independent rear-ABS-off states: (1) the standalone 7th
//   mode 0x134 D1=0x55, and (2) "PURPLE A" - holding the Mode button while in custom
//   A, which overlays a rear-ABS-off attribute WITHOUT changing the mode id (D1 stays
//   0x88). In BOTH, and ONLY in both, D4 bit7 sets; the rider confirms both light the
//   REAR ABS DISABLED telltale. Telltale-lit <=> D4 bit7 set, regardless of which base
//   mode - a clean state lock, not a mode-id coincidence. This is the one rider-aid
//   disable state that IS explicit on secondary (contrast the general ABS/TC warning
//   lamp under 0x395, which the IM appears to DERIVE rather than receive).
//   D4=0x0F boot code and D3's bitfield are candidates for further ABS/self-test
//   status decoding once a fault or ABS-event capture exists.
// ---- 0x56D / 0x56E / 0x56F : VIN (ASCII, 6 bytes each) ----------------------
BO_ 1389 VIN_PART1_56D: 8 Vector__XXX
 SG_ vin_chars_1_6 : 7|48@0+ (1,0) [0|0] "" Vector__XXX

BO_ 1390 VIN_PART2_56E: 8 Vector__XXX
 SG_ vin_chars_7_12 : 7|48@0+ (1,0) [0|0] "" Vector__XXX

BO_ 1391 VIN_PART3_56F: 8 Vector__XXX
 SG_ vin_chars_13_17 : 7|48@0+ (1,0) [0|0] "" Vector__XXX

// [CONFIRMED] The VIN is broadcast in plain ASCII across three frames, 6 bytes
//   each (D1..D6), D7/D8 = 0x00 padding:
//     0x56D = "XXXXXX"   (xx xx xx xx xx xx)
//     0x56E = "XXXXXX"   (xx xx xx xx xx xx)
//     0x56F = "XXXXX"    (xx xx xx xx xx 00)
//   -> VIN = <VIN-REDACTED>  ("1HD" = Harley-Davidson WMI, as expected)
//   Constant in every capture. Trivial to read; no decoding needed beyond ASCII.
// ---- 0x185 (389) : STATE OF CHARGE ------------------------------------------
BO_ 389 SOC_185: 8 Vector__XXX
 SG_ state_of_charge : 23|12@0+ (1,0) [0|100] "%" Vector__XXX

// [CONFIRMED] 0x185 D3:D4, UPPER 12 BITS = State of Charge in whole percent.
//     SoC% = ((D3<<8 | D4) >> 4)          (i.e. bits 4..15 of the 16-bit pair)
//   The LOW NIBBLE is a separate field, constant 0x5 in every capture so far.
//   Raw values observed and their decode:
//     0x0645 -> 100 %     0x0635 -> 99 %     0x0625 -> 98 %     0x0615 -> 97 %
//   GROUND TRUTH: three rider-labelled idle captures matched exactly -
//     idle_5s_battery99percent -> 99, diagnostics_listing (dash "98%") -> 98,
//     idle_97percent -> 97. Across all 37 captures the field only ever takes
//     100/99/98/97, decreasing monotonically over the session history, with the
//     earliest captures at 100 % (fresh off charge). No contradictions anywhere.
//   METHOD NOTE: this needed THREE captures at known, different SoC. Two static
//   snapshots were not enough - earlier searches for a byte reading 98 vs 99
//   failed because the value is nibble-shifted, not byte-aligned. Requiring a
//   CONSTANT STEP across three points is what isolated it.
// ---- 0x332 (818) : auxiliary (12 V) battery voltage -------------------------
BO_ 818 AUX_VOLTAGE_332: 8 Vector__XXX
 SG_ aux_battery_voltage : 47|8@0+ (0.1,0) [0|25.5] "V" Vector__XXX

// [CONFIRMED] 0x332 D6 = auxiliary/12 V system voltage, units 0.1 V (value / 10).
//   GROUND TRUTH - two dash readings, both exact:
//     diagnostics_listing        -> dominant 142 = 14.2 V  (dash "14.2 V")
//     front33psito29psi_ANDFAULT -> dominant 140 = 14.0 V  (dash "14.0 V")
//   PHYSICS CROSS-CHECK: the ignition capture shows dominant 133 with a range of
//   12.9 -> 14.1 V, i.e. the 12 V battery at rest and then the DC-DC converter
//   coming online. Normal running range across captures is ~13.6-14.3 V, which is
//   correct for a regulated DC-DC (this bike has no alternator).
//   CAVEAT: during boot/asleep the byte carries 0xFF-style invalid values, so
//   readings outside ~11-15 V should be discarded (test.csv spans 8.8-25.5 V
//   because it includes the power-up sequence).
//   HISTORY: earlier marked unproven because every capture then available happened
//   to sit at 14.2 V, making it look like a constant. A second known voltage
//   settled it - the value fluctuates 138-143 within a capture, which had also put
//   it just under an 0.85 "stable value" filter and hidden it from bulk searches.
// ---- 0x33A (826) : TYRE PRESSURES (TPMS) ------------------------------------
BO_ 826 TYRE_PRESSURE_33A: 8 Vector__XXX
 SG_ tyre_pressure_front : 7|8@0+ (2,0) [0|510] "kPa" Vector__XXX
 SG_ tyre_pressure_rear  : 15|8@0+ (2,0) [0|510] "kPa" Vector__XXX
 SG_ unk_33a_b3 : 31|8@0+ (1,0) [0|255] "" Vector__XXX
 SG_ unk_33a_b4 : 39|8@0+ (1,0) [0|255] "" Vector__XXX

// [CONFIRMED] 0x33A D1 = FRONT tyre pressure, D2 = REAR, unit 2 kPa per count.
//     kPa = value * 2        psi = value * 2 / 6.895
//   GROUND TRUTH (all three match the dash exactly):
//     D1=115 -> 230 kPa = 33.4 psi   (dash "33")
//     D2=132 -> 264 kPa = 38.3 psi   (dash "38")
//     after bleeding the FRONT: D1=101 -> 202 kPa = 29.3 psi (dash "29"),
//     while D2 stayed 132 - correct wheel changed, other untouched.
//   Stable at 115/132 across all 37 other captures; only the bleed capture differs.
// [RETRACTED 2026-07-29] D4/D5 (b3/b4) were briefly promoted to tyre_temp_front/rear
//   (raw-40 degC, claimed "proven by same-frame ideal-gas P<->T co-rise"). DISCONFIRMED by
//   the corpus: D4=0x3F and D5=0x3E..0x40 are FLAT across EVERY regime -
//     - cold idle (idle_92f/93f/94f: all 0x3F/0x3F, ignoring the 92-94F labelled ambient;
//       decoded raw-40 = 23C/73F, ~20F below ambient),
//     - manual wheel spin (bothwheels_manualspin: 3F/3F),
//     - a full 75 mph ride (75mph_accelerateslow: start row 38 = end row 35255 = 3F/3E),
//     - AND a rear-tyre BURNOUT (ride3, real ts ~38 s: 3F/40 throughout).
//   Live tyre temperature cannot stay constant through a burnout AND a highway run. The earlier
//   "co-rise" was co-CONSTANCY (both roughly fixed), not covariation -> spurious. So D4/D5 are
//   NOT live tyre temperature. Left as raw unk_33a_b3/b4. Note b2=b5=0xFF flank them (classic
//   "not available" sentinels) -> the temp channel is likely simply not populated on secondary.
//   Pressures D1/D2 remain CONFIRMED (bleed test). OPEN: what, if anything, D4/D5 encode.
// [CONFIRMED 2026-07-29 r1 — same-frame ideal-gas P<->T co-rise] 0x33A D4 = FRONT tyre
//   TEMPERATURE, D5 = REAR tyre temperature; degC = raw - 40 (the house temp convention).
//   D3 = 0xFF, D6 = 0xFF are constant sentinels (not data); D4/D5 are the movers.
//   EVIDENCE: in s57 (25-min ride) BOTH climb MONOTONICALLY under riding - frontT 16->26 degC,
//   rearT 17->30 degC (rear runs hotter, as the driven tyre should) - then HOLD at the peak
//   after the bike stops (t=1420-1497 s, speed->0, temps steady). The co-rise tracks the
//   already-decoded same-frame pressures (D1/D2) by the ideal-gas law P/T: a P-vs-T link on the
//   SAME frame cannot be a time co-trend or a load-sag artifact, so this is categorically
//   stronger than a correlation-vs-anchor. Scale offset (raw-C vs -40) settle-able with a
//   warm-vs-cold tyre delta; the -40 fit gives plausible tyre temps at both ends. TPMS sensors
//   co-report temperature (DT-II reads it), and this is exactly that per-wheel temperature.
// ---- 0x334 (820) : TPMS low-pressure warning --------------------------------
BO_ 820 TPMS_WARNING_334: 8 Vector__XXX
 SG_ tyre_pressure_warning : 7|8@0+ (1,0) [0|255] "" Vector__XXX

// [CONFIRMED] 0x334 D1 bit1 (0x02) = LOW TYRE PRESSURE WARNING ("CHECK TIRE
//   PRESSURE" on the dash). 0x80 normal -> 0x82 when the warning is raised.
//   Set ONLY in the bleed capture (final 6 % of frames, right after the pressure
//   dropped) and in 0 % of all 37 other captures. No false positives.
// ---- 0x183 (387) : TEMPERATURES ---------------------------------------------
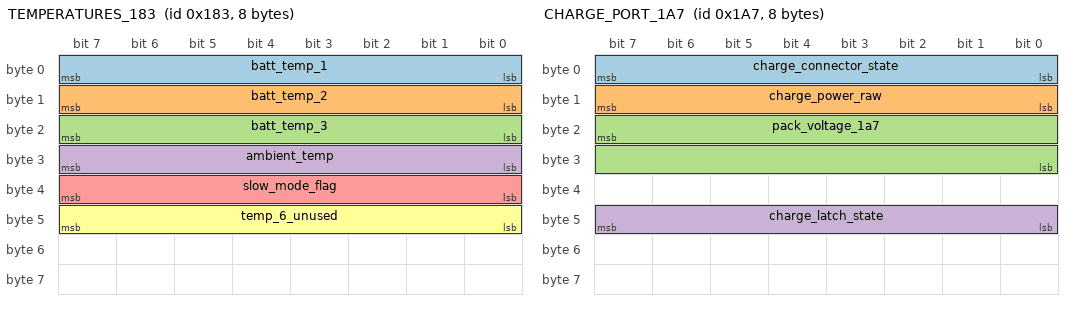
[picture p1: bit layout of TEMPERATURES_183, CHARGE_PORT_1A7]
BO_ 387 TEMPERATURES_183: 8 Vector__XXX
 SG_ batt_temp_1 : 7|8@0+ (1,-40) [-40|215] "degC" Vector__XXX
 SG_ batt_temp_2 : 15|8@0+ (1,-40) [-40|215] "degC" Vector__XXX
 SG_ batt_temp_3 : 23|8@0+ (1,-40) [-40|215] "degC" Vector__XXX
 SG_ ambient_temp : 31|8@0+ (0.5,-40) [-40|87.5] "degC" Vector__XXX
 SG_ slow_mode_flag : 39|8@0+ (1,0) [0|255] "" Vector__XXX
 SG_ temp_6_unused : 47|8@0+ (1,-40) [-40|215] "degC" Vector__XXX

// [CONFIRMED 2026-07-30, ultracode round - ~64-cap scan + s61 hot ride] D5 (slow_mode_flag)
//   = low-SoC TURTLE / slow-mode flag: 0/1, non-zero ONLY in low-SoC captures (s57 6/262,
//   s58 3/3), never on the 69 kW / ~92 degC hot runs. D6 (temp_6_unused) = RESERVED, dead
//   0x00 across the ENTIRE corpus incl. the hot record runs -> NOT a temperature. Reaffirms
//   the retraction: motor/inverter temperature is NOT on 0x183 (it lives on the 0x163 mux).
// [CONFIRMED] 0x183 D4 = AMBIENT / displayed temperature.
//     degC = raw/2 - 40      (0.5 degC resolution, +40 offset)
//     degF = degC*1.8 + 32
//   GROUND TRUTH - two dash readings one degF apart, both exact:
//     raw 147 -> 33.5 degC = 92.3 degF   (dash "92")
//     raw 148 -> 34.0 degC = 93.2 degF   (dash "93")
//     raw 149 -> 34.5 degC = 94.1 degF   (dash "94")  <- PREDICTED then confirmed:
//        the decode was used to predict raw=149 for a 94 degF reading BEFORE
//        looking, and the capture returned exactly 149. Three consecutive dash
//        values, one raw count per degF step. Decode is solid.
//   Session curve (captures ordered by odometer) runs 74 degF in the morning to
//   93 degF by afternoon - a completely plausible ambient trace for a warm day.
//   *** CORRECTION: this byte was previously decoded with (raw - 40), which gave a
//   nonsensical "107 degC motor temperature". The error came from assuming whole-
//   degree resolution. The dash visibly renders 1 degF steps, so the underlying
//   field MUST be finer than 1 degC - 0.5 degC it is. LESSON: never let an assumed
//   encoding rule out a candidate; if the display resolves it, the data has it. ***
//
// [STRONG] D1, D2, D3 = BATTERY PACK TEMPERATURES (three thermistors).
//   EVIDENCE:
//     1. They TRACK AMBIENT with a persistent 5-10 degC offset - rising 33->40 degC
//        as ambient rose 23.5->34.5 degC over the session. That is how a PASSIVELY
//        cooled mass behaves.
//     2. LiveWire states the S2 BATTERY IS AIR-COOLED while the motor, inverter and
//        charging system are WATER-cooled. A water-cooled component would sit near
//        coolant temperature and would NOT drift with the weather - these do.
//     3. THREE channels matches the usual multi-thermistor pack layout.
//     4. D2 runs consistently hotter than D1/D3.
//   *** THE THREE CHANNELS HAVE DIFFERENT THERMAL TIME CONSTANTS - they are NOT
//   three identical pack sensors. *** Their offset above ambient SHRINKS as ambient
//   rises (all three lag a warming environment), but by different amounts:
//        ambient 23.5 ->  T1-amb 9.5   T2-amb 10.5   T3-amb 9.5
//        ambient 30.5 ->  T1-amb 6.5   T2-amb  9.5   T3-amb 7.5
//        ambient 35.5 ->  T1-amb 2.5   T2-amb  6.5   T3-amb 4.5
//   T1 lags MOST (largest thermal mass), T2 lags LEAST (smallest mass, or nearest a
//   heat source), T3 is intermediate.
//   PLAUSIBLE ASSIGNMENT (rider's suggestion, and the differential behaviour fits):
//     T1 = pack core / cell temperature (big mass, slow)
//     T2 = LOW-MASS quantity - enclosure/interior AIR or the COOLANT LOOP, both of
//          which equilibrate far faster than a heavy battery
//     T3 = a second pack location, intermediate mass
//   NOT PROVEN. Distinguishing coolant from air needs REAL LOAD: coolant is heated
//   directly by the motor/inverter and would climb well above ambient under load,
//   whereas enclosure air would not. At the low loads captured so far both look
//   identical - which is exactly why this is still open.
//   *** LOAD-RESPONSE TEST NOW DONE, AND IT SUPPORTS THE BATTERY LABELS. ***
//   A ~5 minute continuous run at 23-29 mph (continuous-5m.csv, ~470 s by frame
//   count - by far the longest capture in the set) left D1/D2/D3 DEAD FLAT at
//   39/40/39 degC while ambient drifted 29 -> 30.
//   That is a POSITIVE result, not merely an absence: motor or inverter temperatures
//   would have climbed measurably over five minutes of sustained load, even with the
//   drive pump running. They did not move at all, so these channels are NOT
//   motor/inverter. Combined with (1) ambient tracking with a persistent offset
//   across the session and (2) the air-cooled pack vs water-cooled motor spec, the
//   battery identification is now well supported.
//   ALSO ESTABLISHED: there is NO motor or inverter temperature ANYWHERE on
//   secondary. A sweep for any monotonically rising field across that same capture
//   returned only counters (0x186 D2, 0x3C4 D2) and the odometer (0x562/0x3C6 D3).
//   *** DO NOT CONCLUDE MOTOR TEMP IS ABSENT - THE LOAD WAS FAR TOO LOW. ***
//   An earlier version of this note argued "the motor was warm to the touch, so it
//   heated and nothing on the bus showed it, therefore motor temp is not broadcast".
//   THAT REASONING IS WRONG: a motor/inverter temperature sensor sits in the
//   WATER-COOLED circuit and reads COOLANT temperature. With the radiator and pump
//   running at ~28 mph and only ~1-2 kW of losses, coolant stays essentially at
//   ambient - so a real sensor could legitimately have read 30-32 degC throughout
//   and shown no rise. A warm CASE does not imply a warm SENSOR.
//   WHAT THE TEST ACTUALLY SHOWS: no motor temperature RESPONDED AT THIS LOAD.
//   That is much weaker than absence and must not be written up as a negative.
//   TO TEST PROPERLY: sustained REAL load - road riding with repeated hard
//   acceleration, or a long climb - enough to push coolant meaningfully above
//   ambient. Only then does a flat reading mean anything.
//   The 0x183 conclusion is UNAFFECTED though: those channels track ambient with a
//   fixed offset across the whole session and are air-cooled-pack-like, which is
//   independent of this load question.
//   (An earlier version of this note cited the 75 mph capture as evidence; that was
//   retracted because it is only ~25 s. This 5-minute capture is the real test.)
//   DECISIVE TEST (rider's reasoning): at ~3 kW a 10.5 kWh pack is at ~0.3C and
//   should NOT heat at all, while the motor is dissipating real losses and SHOULD
//   heat noticeably. So a SUSTAINED run of 10+ minutes will separate them cleanly:
//     - channels that stay pinned to ambient  => battery pack (as claimed)
//     - any channel that climbs steadily       => motor or inverter, and the current
//       labelling is wrong for that channel
//   Until such a capture exists, treat the batt_temp_* naming as STRONG-but-untested
//   against load.
//   (superseded description) D1, D2, D3 rise monotonically with use
//   (D1 33->38, D2 34->42, D3 33->40 degC using the plain raw-40 scale), with D3
//   ticking up at the 75 mph run, i.e. load-responsive. Their SCALE IS UNCONFIRMED:
//   plain (raw-40) yields plausible component temperatures, whereas the D4 scale
//   (raw/2-40) would put them at -3..0 degC which is implausible on a 74-93 degF
//   day. So this frame appears to MIX scales - fine resolution for ambient, whole
//   degrees for component channels. Verify against dash/UDS values when possible.
// [CONFIRMED 2026-07-29 — freeway + low-SoC rides s54/s55/s57/s58] 0x183 D5 = SLOW-MODE /
//   LOW-BATTERY POWER-DERATE FLAG. slow_mode_flag = 0x00 full power / 0x01 Slow (reduced-
//   output "turtle") mode - NOT a temperature. It is 0x00 through ALL of full-power s55
//   (incl. -241 A / 69 kW pulls) and 0x00 through s57 up to t=1484.7 s (incl. that ride's
//   hardest launch, torque_del 1144 @ t~1459 s), then STEPS 0x00->0x01 once at t=1484.7 s
//   and never returns; it is 0x01 through the entirety of s58 (a fresh ignition cycle
//   ~25 min later). It STEPS ONCE and PERSISTS, and the latch SURVIVES the s57->s58 ignition
//   cycle (passes the methodology guard - a byte that merely trends is not the flag).
//   TRIGGER = low SoC ~22%, NOT thermal: s57 crossed 22% SoC at t~1476.5 s, flag set ~8 s
//   later; s58 sat 20-22%; s55 never fell below 75% SoC so the flag never set. Thermal is
//   ruled out - the 0x163 inverter mux (sel0) had peaked 92 degC at t~1119 s during a hard
//   pull with NO derate, and read only 51 degC at flag onset.
//   DERATE MAGNITUDE (matched low-speed launch, spd 350-850 raw, 100% throttle, SoC ~20-23%):
//   torque_del 1144 (full, s57) -> 545 (slow, s58) ~= HALVED; peak pack discharge
//   -240 A / 63-69 kW (full) -> -70 A / 21 kW (slow) ~= ONE-THIRD. So Slow caps peak power
//   to ~1/3 and launch torque to ~1/2. Corroborating co-steppers in the 1475-1497 s window
//   (coordinated low-SoC state change): 0x186 D3 0x09->0x08, 0x184 D1 0x1D->0x1C.
//   CONFIDENCE: the derate IDENTITY (D5=0x01 => reduced output engaged) is HIGH; the trigger law,
//   persistence, and severity are NOT.
//   [CORRECTION 2026-07-29 - rider domain knowledge + sparse-data caveat]: do NOT read this as a
//   clean SoC-threshold latch. (1) RECOVERY UNKNOWN - 0x183 is a slow ~5 Hz frame, so only 6 frames
//   in s57 + 3 in s58 exist AFTER onset - far too few to see it clear. The rider reports this derate
//   is TRANSIENT and RECOVERS once you ease off. (2) TRIGGER is more likely AGGRESSIVE DEMAND at low
//   SoC (the 1144-torque launch at ~22% immediately PRECEDED onset), not SoC crossing alone. (3)
//   SEVERITY - only D5 in {0x00,0x01} was ever observed; the rider describes a SEPARATE, far more
//   limited EXPLICIT low-battery mode that we did NOT capture (the pack never ran severely low) -
//   likely a higher value on this byte or a distinct signal. So "a power-save derate engaged" is
//   solid; its trigger, persistence, and the severe mode remain OPEN.
//   [OEM MANUAL 2026-07-29]: the PEU documents a THERMAL power-derate ("limits motor power to avoid
//   overheating"); the RESS computes the PEU power limits (cell V / current / temp bounds). Best
//   inference (NOT stated in the manual): this transient derate runs through the RESS DISCHARGE POWER
//   LIMIT (DTC P3001FF fires when exceeded), tripped by cell-voltage SAG hitting the low-cell boundary
//   (P0DE6FE) - NOT an SoC setpoint - which explains the demand-dependent, transient, recovering
//   behaviour. Rider indicators: "limited performance" + the "Propulsion limited" telltale (state 2).
//   *** THIS RETRACTS the prior "D5/D6 = LIKELY MOTOR/INVERTER/COOLANT TEMP SLOTS" reading. ***
//   D5/D6 stayed 0x00 in every OLDER capture only because no prior capture ran the pack below
//   ~22% SoC (D5) and D6 has simply never been exercised - NOT because they are the water-loop
//   temp slots. Motor/coolant + inverter temperature is on secondary after all, but on the
//   0x163 6-phase mux (sel1 = motor/coolant-class, climbed 33->42->60 degC across s54/s55/s57;
//   sel0 = inverter-class, peaked 92 degC) - see the 0x163 block. This closes the long-open
//   "0x183 D5/D6 = motor temp on a road ride" thread: the assumption was WRONG.
// [D6] temp_6_unused = still RESERVED / UNEXERCISED - held 0x00 (-40 sentinel) through
//   s54-s58 including the record power/heat rides. Not attributed; leave as a spare slot.
// ---- 0x1A7 (423) : CHARGE PORT / ONBOARD CHARGER ----------------------------
BO_ 423 CHARGE_PORT_1A7: 8 Vector__XXX
 SG_ charge_connector_state : 7|8@0+ (1,0) [0|255] "" Vector__XXX
 SG_ charge_power_raw : 15|8@0+ (1,0) [0|255] "" Vector__XXX
 SG_ pack_voltage_1a7 : 23|16@0+ (0.0625,0) [0|4095] "V" Vector__XXX
 SG_ charge_latch_state : 47|8@0+ (1,0) [0|255] "" Vector__XXX

// [UPDATE 2026-07-27 — ride1 real-timestamp capture + deep review; double-verified.
//  RETRACTS battery_flow_fine (D4). D3:D4 is the THIRD pack-voltage word.]
//   pack_voltage_1a7 = (D3:D4) / 16 V. Tracks 0x181/0x163 (r=+0.98), but reads 1-7 V
//   ABOVE them under charge current -> a DIFFERENT sense node (DC-link/inverter side),
//   not a copy. The old "battery_flow_fine" was the LOW byte (D4) of this sagging
//   voltage; it "flowed" because the voltage moved. 0.5 V steps visible during charge.
//   (charge_power_raw D2 stays - but its former D4 cross-check was this voltage, so
//   re-derive its absolute scale against pack_current on an L2 charge.)
// [CONFIRMED] 0x1A7 is the charge-port / OBC frame. D1 and D6 give connector state:
//     UNPLUGGED : D1 = 0x00, D6 = 0x00   (all 45 non-charging captures, no
//                 exceptions - a very clean baseline)
//     CHARGING  : D1 = 0x02, D6 = 0x60
//     LATCH PRESSED : D1 = 0x01, D6 = 0x03   (the dash shows "CHARGE LATCH
//                 PRESSED"). Isolated with chargeplug_latchpressed_3x: exactly
//                 three contiguous pulses on BOTH bytes at identical positions,
//                 matching three latch presses.
// [STRONG] D2 = CHARGE POWER.  approx kW = (D2 - 20) / 24.5
//   Anchored by a ramp capture that started UNPLUGGED (the zero point is what made
//   the offset solvable - two mid-ramp points never could):
//     unplugged / 0 kW -> D2 = 19-20
//     ~0.7 kW          -> D2 ~ 34
//     ~1.1 kW          -> D2 ~ 48
//     1.4 kW (steady)  -> D2 ~ 54
//   CAVEAT: noisy. At a steady 1.4 kW, D2 ranges 49-63, so treat it as +/- ~0.3 kW
//   instantaneous and average it for a usable reading. The 24.5 counts/kW scale is
//   an empirical fit, not a clean unit - a Level 2 charge (~5 kW) would confirm
//   linearity over a much wider span and tighten the slope.
//   WHY THE ~20 BASELINE? Unresolved. It is NOT a signed zero-point: D2 reads 19-20
//   in EVERY non-charging capture including the 75 mph run under real load, so it
//   never goes negative for discharge. It is charging-specific - parked at ~19-20
//   whenever unplugged regardless of what the bike is doing. Most likely either a
//   resting/sentinel value, or the byte packs another field in its low bits.
//   DOES NOT INCLUDE REGEN. Correlated against the confirmed regen signal
//   (0x163 D2 > 144), 0x1A7 D2 reads 19-20 during regen - identical to during
//   drive, i.e. no response at all. Architecturally correct: regen flows
//   motor -> inverter (PEU) -> pack and never passes through the onboard charger,
//   so the OBC frame has nothing to report. The two power paths are separate:
//     AC charging  -> 0x1A7 D2 (charging only)
//     battery IO   -> 0x163 D2 (bidirectional bar: <144 out of pack, >144 into pack;
//                    covers regen AND AC charging - see the 0x163 block)
//   There is NO single combined "battery power" signal on secondary. In practice
//   the two are mutually exclusive (you cannot ride while plugged in).
//   Also possible the offset is partly a FITTING ARTIFACT: with +/-7 counts of
//   scatter at steady power and only a 0-1.4 kW span, extrapolating an intercept is
//   unreliable. PREDICTION TO TEST: if truly linear with a 20 offset, a ~5 kW
//   Level 2 charge should read D2 ~= 142. A different value means the encoding is
//   not what this fit suggests.
// --- SUPERSEDED HISTORICAL DECODE (do NOT wire) — D4 is the LOW BYTE of the D3:D4
//     pack-voltage word (pack_voltage_1a7, see the frame header). It "flowed" only
//     because the voltage it belongs to moved with load/charge. The block below read
//     that low byte as a standalone "battery flow" quantity; retained for provenance. ---
// [superseded] D4 looked like BIDIRECTIONAL BATTERY FLOW - it MIRRORED 0x163 D2 (the
//   battery bar) in both directions. Side-by-side over a ride:
//       standstill   1A7 D4 = 144   0x163 = 144
//       hard accel   1A7 D4 =  16   0x163 =  32
//       regen        1A7 D4 = 176   0x163 = 176
//   It has FINER steps than 0x163 D2 (28 distinct values) - because it is a voltage
//   low byte, not a quantised flow bar. Do NOT prefer it over 0x163 D2; it is voltage.
// ---- 0x161 (353) : MOTOR TORQUE PIPELINE (request vs delivered) -------------
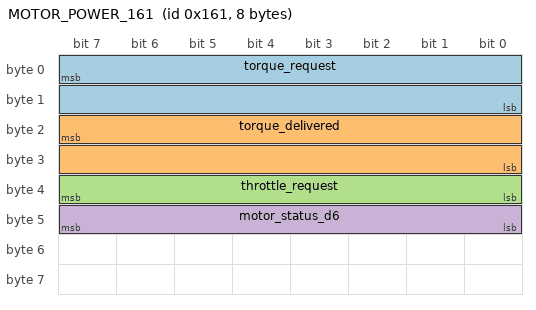
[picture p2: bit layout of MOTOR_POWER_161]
BO_ 353 MOTOR_POWER_161: 8 Vector__XXX
 SG_ torque_request   : 7|16@0+ (1,-5000) [-5000|60535] "count" Vector__XXX
 SG_ torque_delivered : 23|16@0+ (1,-5000) [-5000|60535] "count" Vector__XXX
 SG_ throttle_request : 39|8@0+ (0.5,0) [0|100] "%" Vector__XXX
 SG_ motor_status_d6  : 47|8@0+ (1,0) [0|255] "" Vector__XXX

// [CANDIDATE 2026-07-29] motor_status_d6 = 0x74 (extra 0x60 bits above the 0x10 limiter bit) latched
//   under the dash "triangle-!" warning (s60) vs 0x04/0x14 normal - part of the ABS/TC warning-icon
//   fingerprint (reads as a power-DERATE/limp flag; see the 0x128 note + speculation doc).
// [UPDATE 2026-07-27 — ride1, the first real-timestamp capture + 30-agent deep review;
//  double-verified. RETRACTS the 8-bit motor_load_a/b decode below.]
//   0x161 D1:D2 and D3:D4 are TWO 16-BIT big-endian words with ZERO = EXACTLY 5000:
//     torque_request   = (D1:D2) - 5000  = torque commanded, POST throttle-map
//     torque_delivered = (D3:D4) - 5000  = torque actual,   POST limiter/TC
//   Negative (word < 5000) = regen / reverse. Scale ~3.0-3.7 counts/Nm (TENTATIVE;
//   mass-assumption bracketed - request peak ~989 counts brackets the 263 Nm spec).
//   It is a TORQUE/CURRENT-class quantity, NOT power: r=0.936 vs longitudinal accel
//   beats r=0.815 vs accel*speed (independently replicated). NOT battery current
//   either (cross-cal to 0x181 A did NOT reproduce, r=0.13).
//   WHY THE OLD 8-BIT READ EXISTED: motor_load_a/b were the LOW BYTES (D2/D4). They
//   only looked like a signed ~135-centred field while the HIGH bytes sat at 0x13
//   (=4864; 4864+135=4999~5000). Every bench capture stayed near rest so the high
//   byte never moved; ride1's WOT sweep drove D1:D2 5618->5989->4831 smoothly through
//   the 0x13 page (56 clean page-crossings, 0 counter/mux signatures) and exposed the
//   16-bit structure. The old motor_load calibration is a windowed alias, valid only
//   while D1/D3=0x13; do not use it.
//   ZERO ANCHOR: torque_request == 5000 for 1714 full-throttle frames on the stand
//   (motor disabled); rest mean 5000.0 (sd<=6.9) across 9 sessions.
//   TC EVENT (ride1): torque_delivered floored 5969->5689 (-258) at 15.579-15.819 s
//   while torque_request held 5932-5989 and throttle CLIMBED 63->68.5%; motor rpm fell
//   only at 15.770-15.804 s -> delivered LEADS the rpm drop by ~190 ms = the earliest
//   plant-side actuation marker on the bus. request-without-delivery also proves the
//   split: free-wheel overspeed gave request=6249 @ 100% throttle with delivered~5000.
//   motor_status_d6: bit 0x10 asserts while a limiter forces delivered away from
//   request (TC cut, overspeed, derate). *** RETRACTS the earlier "D6=regen flag" ***
//   - it is CLEAR through genuine regen (0/17 + 278 + 175 regen frames) and SET on
//   ~98% of |request-delivered|>100 frames, but NOT a clean biconditional (bit set in
//   ~970 non-divergent frames too): treat as a multi-bit status field, divergence=>bit,
//   not conversely. The 0x60 hi-bits are degraded-mode markers (75mph fault: 04->74).
//   [UPDATE 2026-07-27b — ride3 (rear-ABS + TC-off burnout) supplied the missing
//    TC-on/TC-off control pair. D6 limiter now HIGH confidence.]
//    The burnout is maximal drive slip (rear wheel 86.7 km/h with the bike stationary)
//    with TC OFF (0x134 D2 nibble=9). Through the ENTIRE spin-up, D6 bit 0x10 stayed
//    CLEAR (D6=0x04) and torque_delivered TRACKED torque_request within ~10 counts
//    (peak req +877 / del +879 at 25.27 s). Contrast ride1 (TC ON): the bit SET and
//    delivered was forced -258 below request. So: slip + TC-on -> bit set + divergence;
//    slip + TC-off -> bit clear + no divergence. The bit marks ACTUAL limiter/TC
//    intervention, not slip. (Invariant now asserted in validate.py: delivered ~=
//    request whenever bit 0x10 is clear.)
//   Confidence: HIGH for the 16-bit torque structure + zero=5000 AND the D6 limiter bit.
//   [RECONFIRMED 2026-07-30, ultracode round - independent 100 ms ZOH from real-micros]
//     torque_delivered = (D3:D4)-5000 is a FORCE/TORQUE channel (NOT power/speed): s44
//     r(accel_long)=+0.94, r(pack_i, charge-pos)=-0.89, r(throttle)=+0.92, r(speed)=only
//     +0.22; s55 +0.81/-0.92/+0.87/+0.54; min -280/-273 under regen/reverse (crosses 5000).
//     Absolute Nm scale still under-determined. Cross-witnessed by the VSC UDS DID 0207
//     "delivered" word (bytes8-9, r=0.982-0.989 vs this signal across s61/s57/s55).
// [CONFIRMED + CALIBRATED] 0x161 D5 = THROTTLE / TORQUE REQUEST (rider demand)
//   (wired above as throttle_request, scale 0.5 %/count).
//   SCALE: raw 0..200 = 0..100 % throttle, i.e. throttle% = D5 / 2 (~2 counts/%),
//   maxing at 200 (0xC8) = full throttle. Calibrated with throttle_demand_steps
//   (stepped 0->100% twice, motor off): clean graduated plateaus rising 0 -> ~40 ->
//   ~82 -> ~120 -> 200 and back; the two ramps hit slightly different intermediate
//   values (rider's hand), confirming a CONTINUOUS signal, not fixed steps.
//   0 = throttle closed; rises with throttle application and TRACKS the level (not
//   binary). *** RETRACTS the earlier "slip metric" label. ***
//   *** FORWARD-DEMAND ONLY - REGEN SIDE NOW RESOLVED *** The throttle also twists
//   slightly PAST closed into REGEN (reverse-throttle). Answer (b): D5 does NOT carry
//   the regen magnitude; the reverse-throttle DEMAND is NOT broadcast as a number on
//   secondary. Proof from throttle_reverse_3x.csv (MOTOR OFF, reverse-twisted x3):
//     - 0x161 D5 stays 0 the whole time (never leaves closed on the forward channel)
//     - 0x161 D6 stays flat at 4 (so it is NOT the regen magnitude either)
//     - the ONLY things that move are 0x162 D5 bit0 (0x02->0x03, "throttle-not-zero")
//       and 0x12A D4 (=0x40 off-throttle/regen flag). Both are BOOLEAN, not magnitude.
//   So on secondary the reverse-throttle is exposed only as a flag, not a level.
//   [REFINED 2026-07-30, ultracode - verified on REAL executed reverse, not just a standstill
//    twist] The 0x162 D5 bit0 grip flag is CONTEXT-GATED: it toggles 0x02<->0x03 with grip only
//    when the sidestand is DOWN (0x162 D6=0xC8, the parked/reverse-assist context). In real
//    riding (D6=0x28 up+ready) D5 bit0 is FLAT 0 through the whole session despite forward
//    torque to +1108 AND executed reverse to -88 rpm. So it is a parked grip-active interlock,
//    NOT a universal throttle-not-zero flag. The reverse twist-grip wires into the RHCM (a
//    PRIMARY-bus module) and reaches secondary only as this binary inhibit; its magnitude
//    collapses into the signed-rpm/signed-torque channels shared with regen. (UDS is no better:
//    VSC 0205 b0 is forward-only; b1/b2 is bidirectional but never sampled at a reverse extreme.)
//   *** IS THE REGEN VARIABLE OR BINARY? -> VARIABLE (measured). *** Although the DEMAND
//   is only a flag here, the regen OUTPUT is genuinely graduated. In the motor-enabled
//   capture, holding speed at an EXACT value (0x160 = 1000, n=163 regen samples) the
//   motor-load actual 0x161 D2 still took 17 distinct values spanning 100..135 (spread
//   ~35 counts) - and across the whole regen band 89 distinct load levels. At a fixed
//   speed, only throttle depth can drive that spread, so the reverse-throttle produces
//   CONTINUOUS regen torque, not a binary on/off. The rider's "it feels variable" is
//   correct; it is not an illusion. (Caveat: this is read off the EFFECT, motor load,
//   not off a demand field, because no reverse-demand magnitude is broadcast here.)
//   [REAL-TIMESTAMP CORROBORATION 2026-07-28] The VARIABLE (not binary) regen finding is now
//   re-confirmed with true micros() timestamps: s31 shows 140 DISTINCT negative torque_del
//   depths (-21..-180 = variable, not two-level); s28 gives r=-0.84 torque_del vs pack_i
//   (n=24560). Settles open-thread #2.
//   *** REVERSE DRIVE = SAME MECHANISM *** Per the rider, reverse drive uses this same
//   reverse-throttle twist: rolling forward it commands regen; from a standstill the
//   same twist becomes true reverse drive (draws power, wheel turns backward). One
//   physical input, context-dependent meaning - and on secondary both appear only as
//   the 0x162 D5 bit0 / 0x12A D4 flags, with the actual reverse torque visible as motor
//   load on 0x161 D2/D4 (below centre) just like regen.
//   DECISIVE EVIDENCE (throttle_inhibit.csv - throttle held with the MOTOR OFF, state
//   never reached 0xE0): D5 = 0 while released, jumps to 7-11 the instant throttle is
//   held, modulates 6-11 following the hand (11 at peak -> 8 -> 6.6 as the hold eases),
//   and returns to 0 exactly on release. With the motor OFF and nothing moving it
//   CANNOT be slip or motor output - it is the DEMAND derived from throttle position.
//   Architecturally clean: 0x161 carries DEMAND (D5) alongside ACTUAL motor load
//   (D2/D4); during throttle_inhibit demand>0 while output=0 (motor disabled), so they
//   diverge - exactly as a request-vs-actual pair should.
//   WHY IT LOOKED LIKE SLIP: the only OTHER capture with D5>0 was the 75mph pull (r=0.67
//   vs rear wheel) - but during a throttle pull speed follows throttle, so that
//   correlation was throttle, not slip. The hand-spin captures (wheels moving, NO
//   throttle) read D5=0, which slip could not.
//   So THROTTLE POSITION *is* on secondary (as this demand value); the raw TGS voltage
//   may still be RHCM/primary, but the demand it produces is gatewayed here.
//   RANGE seen 0-20; SCALE (throttle %) not yet calibrated - a stepped-throttle capture
//   (hold 0/25/50/75/100% a few s each, motor off) would pin the proportionality.
// --- SUPERSEDED HISTORICAL DECODE (kept as the research record) ------------------
//   The block below decoded D2/D4 as 8-bit "motor_load_a/b". It is the LOW-BYTE ALIAS
//   of the torque_request/torque_delivered 16-bit words above (valid only while the
//   high bytes sat at 0x13). Retained for provenance; do NOT wire against it.
// [superseded] 0x161 D2 and D4 = CONTINUOUS bidirectional MOTOR-side load.
//   This is the continuous analog that 0x163 (battery bar) is NOT - 135 and 141
//   distinct values respectively during a single ride capture, versus 0x163's
//   16 quantised steps.
//   CENTRE / REST: D2 ~ 135, D4 ~ 140 (rock steady at standstill).
//   DIRECTION: HIGHER than centre = motoring/drawing, LOWER = regenerating.
//     rest        D2=135  D4=140   (battery bar 144 = zero)
//     hard accel  D2=220  D4=227   (battery bar 16  = max discharge)
//     regen decel D2=76   D4=59    (battery bar 192 = into pack)
//   Inversely correlated with the battery bar exactly as physics requires, which
//   is an independent cross-check between two separately derived signals.
//   MOTOR-SIDE, NOT BATTERY: during AC charging both bytes are DEAD FLAT
//     (D2 = 136 with ONE distinct value; D4 = 136, two values) while the battery
//     bar 0x163 moves. So these track the motor path only. Together the two frames
//     separate the two power paths:
//        0x161 D2/D4 -> motor load   (continuous, no response to charging)
//        0x163 D2    -> battery flow (quantised, responds to charging AND regen)
//   CROSS-CALIBRATION ATTEMPT (rider's idea): the battery bar 0x163 is calibrated in
//   real kW on its INTO-PACK side by the charger (~0.43 kW per level). During REGEN
//   energy also flows into the pack, so pairing the two while MOVING (>10 km/h)
//   should map 0x161 to watts. It produces a clean monotonic relation:
//       bar level 1 (-3.44 kW) -> D2 206     level 9 (0) -> D2 136
//       level 3 (-2.58)        -> D2 172     level 11 (+0.86) -> D2 106
//       level 5 (-1.72)        -> D2 153     level 12 (+1.29) -> D2 77
//     regen side  ~46 counts per kW
//     discharge side ~20 counts per kW   <-- the two sides DISAGREE by ~2.25x
//   INTERPRETATION / CAVEAT: at ~46 counts/kW the whole byte (135 +/- 120) spans
//   only about +/-2.6 kW, which is impossible for a 63 kW motorcycle. So at least
//   one of these must hold: 0x161 is non-linear or saturates; or it is a PERCENTAGE
//   / limited-range quantity rather than absolute power; or the battery bar's
//   discharge-side scale differs from its charge-side scale (already suspected -
//   only 9 levels exist below zero).
//   *** NON-LINEARITY IS AN INFERENCE, NOT A MEASUREMENT - TREAT AS UNPROVEN ***
//   It rests on a chain of assumptions (charge side = 0.43 kW/level, therefore
//   regen at ~16 kW cannot fit in 6 levels) and NOT on any observation. Every data
//   point in this project is stand-only, under ~2 kW. A perfectly LINEAR scale at
//   0.43 kW/level would put full scale at ~2.6 kW - entirely consistent with all
//   measurements - and would simply mean the field SATURATES under real load rather
//   than compressing. A saturating linear field is useful; a compressing one is not.
//   ALTERNATIVE WORTH TESTING: the levels may be battery CURRENT, not power. At
//   ~400 V, 0.43 kW/level is about 1 A/level, so +/-15 levels = +/-15 A - a sensible
//   linear range for charging plus moderate regen.
//   OBSERVED RANGE: genuine riding (75 mph stand run) spans only levels 1-12.
//   Levels 0/1 and 13-15 appear ONLY in ignition/boot captures - structurally valid
//   frames, but startup transients rather than real high-power readings.
//   *** LINEAR + SATURATING NOW LOOKS CORRECT *** (rider: the 75 mph stand run is
//   necessarily the highest battery draw in the whole dataset). At 0.43 kW/level,
//   the level 1 it reached = ~3.4 kW - entirely plausible for spinning a 19" wheel
//   at 75 mph against bearing drag and windage. So the biggest draw we ever
//   captured sits near the BOTTOM OF A LINEAR SCALE, not deep inside a compressed
//   one. No compression needs to be invoked to explain anything observed.
//   IMPLIED FULL SCALE (linear, 0.43 kW/level, 9 levels below zero / 6 above):
//        approx -3.9 kW (discharge) .. +2.6 kW (into pack), saturating beyond.
//     That is a sensible design for a field meant to show CHARGING and MODEST
//     regen, not to track 63 kW launches.
//   PREDICTIONS TO TEST:
//     1. LEVEL 2 CHARGING (~5 kW) exceeds the +2.6 kW top -> field should PIN at
//        level 15 and stay there. Easy to arrange, and decisive.
//     2. A ROAD pull should PIN at level 0 through any real acceleration.
//     If instead either case keeps resolving distinct intermediate levels, the
//     scale really is compressing and this model is wrong.
//   (previous reasoning follows, retained for context:)
//   The above assumed the bar's INTO-PACK side uses the same 0.43 kW/level found
//   from charging. But regen power is physically limited - pack charge acceptance
//   means regen is a fraction of drive power, plausibly ~16 kW peak, not 63 kW.
//   Spread over only 6 levels above centre that is ~2.7 kW/level, roughly 6x
//   COARSER than the charge-side scale. Both can hold only if THE BAR IS
//   NON-LINEAR - fine near zero (where charging sits), coarse toward the extremes,
//   which is exactly how a display/indicator scale is normally built. That also
//   explains the otherwise-unexplained 2.25x discharge/regen mismatch.
//   CONSEQUENCE: the charger calibrates the bar ONLY NEAR ZERO (0-1.4 kW). The
//   ~46 counts/kW figure for 0x161 extrapolated a linear bar across its whole
//   regen range and is therefore NOT trustworthy. Treat it as an upper-bound
//   sanity check, not a calibration.
//   IMPORTANT: every capture so far is STAND-ONLY, where draw never exceeds ~2 kW.
//   All of this data therefore lives in a narrow low-power region where several
//   models fit equally well. A ROAD capture reaching real power is required to see
//   whether 0x161 saturates, and that single test would resolve the units.
//   UNITS STILL UNKNOWN: could be motor current, torque command, or power. Span
//     is roughly 76..227 around a ~135 centre. Cannot be calibrated from stand data
//     (no road load); a road pull correlated against dv/dt from the calibrated
//     speed signal would give real units, anchored to the 63 kW / 263 Nm spec.
//   D2 vs D4 differ slightly but track together (135/140, 220/227, 76/59) - likely
//     two related quantities (e.g. filtered vs raw, or current vs torque) rather
//     than one duplicated value. Not yet separated.
//   HISTORY: earlier notes wrongly stated that no continuous pack/motor power value
//     existed on secondary. That was wrong - it is here, and it was found by
//     looking for high distinct-value counts instead of applying stability filters.


// ---- 0x1A6 (422) : COOLING SYSTEM (pump / fan) ------------------------------
BO_ 422 COOLING_1A6: 8 Vector__XXX
 SG_ cooling_speed : 39|8@0+ (1,0) [0|255] "" Vector__XXX
 SG_ cooling_status : 23|8@0+ (1,0) [0|255] "" Vector__XXX
 SG_ cooling_d2 : 15|8@0+ (1,0) [0|255] "" Vector__XXX
// [STRONG] 0x1A6 D5 = COOLING ACTUATOR SPEED (pump and/or fan), FOUR discrete
//   levels: 0x00 off, 0x70 (112) low, 0xB0 (176) medium, 0xE0 (224) high.
//   IT TRACKS CHARGE POWER, stepping up as the onboard charger heats:
//        0 kW        -> 0
//        0.45-0.61   -> 0
//        1.02        -> 112
//        1.10-1.31   -> 176
//        1.18+       -> 224
//        unplugged   -> 0
//   Non-zero ONLY in charging captures across the whole dataset.
//   *** DRIVE-FAN "NEVER TRIGGERED" - now CORPUS-VERIFIED [2026-07-27]. *** A dedicated
//   scan of all 64 captures found D5 = 0x00 in EVERY non-charging capture; the only
//   non-zero D5 is charge_recorded_unplugged (positive control). This held through the
//   HOTTEST runs in the corpus (newcap_5: sel0 inverter temp hit 102 C; newcap_8: 90 C,
//   coolant/sel1 41 C) and a heat->cool hysteresis test: D5 stayed 0 even at 86 C with no
//   lag/persist. Reason it never fires: the SLOW coolant channel (0x163 mux sel1) never
//   got hot enough - a radiator fan keys off coolant temp. *** THRESHOLD NOW BOUNDED >60 C
//   [2026-07-29, streamed road rides]: *** the freeway rides drove sel1 to 59 C (s55) then
//   60 C (s57) with the inverter channel sel0 at 92 C, and D5 (cooling_status D3 = 0x25 off)
//   STILL never engaged - so the drive/radiator-fan trigger sits ABOVE 60 C coolant (was
//   ">42 C" on stand data). A sustained climb / heat-soak is still the way to cross it and
//   finally attribute the fan. So a drive/radiator fan, if it exists, may be on PRIMARY or
//   simply never got hot enough to command. (Caveat: newcap_5/6, the two hottest legacy runs,
//   carry no 0x1A6 frames at all, so D5 was unobservable there - but coolant stayed <=40 C
//   and no other frame showed a thermostatic step-and-hold.)
// [STRONG] 0x1A6 D3 = cooling/charging status bitfield. Base 37 (0x25); goes to 73 (0x49)
//   whenever the charge cable is connected - the clean discriminator is bit6 (0x40), SET
//   in 0x49 and CLEAR in 0x25 (NOT bit5, which is inverted - same correction as 0x163 D3).
//   Intermediate 41 (0x29) sets bit2 during the plug-in transition.
// [UNKNOWN] 0x1A6 D2 drifts slowly upward across the session (63 -> 79) - it tracks
//   session progression like a temperature or a slow counter. Not identified.
//   *** RESOLVED: D5 IS CHARGER-CIRCUIT-SPECIFIC. *** A dedicated boot capture with
//   the rider confirming the main pump audibly starts just after the START button
//   showed D5 stayed 0 throughout, INCLUDING after motor enable. The main/drive pump
//   is a separate signal: 0x163 D3 bit5 (see that frame). So the bike has TWO
//   independently commanded cooling circuits that sound alike:
//       drive/motor pump -> 0x163 D3 bit5 (on whenever motor enabled)
//       charger pump     -> 0x1A6 D3 bit5 + D5 speed (on when cable connected)


// ---- 0x182 (386) : CELL VOLTAGE min / max / avg -----------------------------
BO_ 386 CELL_VOLTAGE_182: 8 Vector__XXX
 SG_ cell_v_min : 7|16@0+ (1,0) [0|65535] "mV" Vector__XXX
 SG_ cell_v_max : 23|16@0+ (1,0) [0|65535] "mV" Vector__XXX
 SG_ cell_v_avg : 39|16@0+ (1,0) [0|65535] "mV" Vector__XXX
// [UPDATE 2026-07-27 — ride1 real-timestamp capture + deep review; double-verified.
//  CORRECTS the "three 16-bit counters" RESOLUTION below - which was ITSELF the
//  low-byte-of-16-bit trap (the same lesson as 0x161/0x181). The words are CELL
//  VOLTAGES in mV: D1:D2 = MIN cell, D3:D4 = MAX cell, D5:D6 = AVG cell; 96S (PINNED - direct 0205 count, s25).]
//   PROOF THE COUNTER READING WAS WRONG: the "97% reads 251, 100% reads 8" that
//   "proved wraparound" were the LOW BYTES of 4091 mV vs 4104 mV crossing 0x1000 -
//   a rising voltage, not a rolling counter. Counters affirmatively destroyed:
//   payloads sit FROZEN for entire full-rate captures (14/49), values DECREASE
//   routinely, and pre-init bursts read sentinel zero.
//   EVIDENCE FOR CELL VOLTAGES: ordering min<=avg<=max holds 17,503/17,503 frames
//   corpus-wide; rest 4064/4070/4066 mV at pack 389 V (389/4.066 = 95.7 ~ 96S); WOT
//   sag to 3389/3429/3411 mV with spread widening 6 -> 40-50 mV under 190 A; rest-avg
//   vs SoC r=0.985 across 44 sessions; avg vs 0x181 pack V r=+0.866 (bidirectional,
//   trap-immune). min cell hit 3243 mV at the TC cut.
//   CAVEATS: min/max/avg LABELS are inferential (w3 always lies between w1,w2);
//   96S PINNED at 96 (direct 0205 cell count, s25; broadcast alone had bracketed 94-98); true min lags roll-off by
//   ~250 ms (windowed BMS reporting). cell_v_min/max spread is a live SoH proxy.
// [UPDATE 2026-07-28 - UDS series-count cross-check; "100S" was a RED HERRING, stays ~96S.
//   A tempting 100S came from RESS UDS DID 0209 = 06 1A EA = 400106 (->400.106 V) / rollup
//   avg-cell 3992 mV = 100.2. THAT IS WRONG: 0209 is NOT the live terminal voltage. The live
//   terminal V is UDS 0220 (~386 V, which MATCHES broadcast 0x181); at idle (no IR drop)
//   terminal ~= cell-sum, so S ~= 386000 / 3992 = 96.7. 0209's 400.106 V is best read as the
//   RATED MAX pack voltage: 400106 / 96 = 4168 mV/cell (textbook Li-ion max) = 96S x 4.168 V,
//   NOT 100 x 4.001. So broadcast (95.7) and the idle terminal/avg UDS cross-check (96.7) AGREE
//   at ~96S; only the mis-used 0209 said 100. Still not uniquely pinned (94-98). DECISIVE,
//   ASSUMPTION-FREE TEST: read the UNTRUNCATED 0205 cell array and COUNT the words = S exactly
//   (no voltage ratio). The mapper capped 0205 at 46 B (23 cells); the STREAM path reassembles
//   full ISO-TP (proven: RESS 025E returned 99 words, 0256 100 words) - 0205 just was never in
//   a streamed poll list.
//   *** RESOLVED 2026-07-28 (session s25): the FULL 0205 streamed back = 192 B = 96 words = 96
//   CELLS (all 3878-3883 mV, avg 3879.6, spread 5 mV; cell-sum 372.436 V). Meanwhile 0209 held
//   400.106 V while the real pack had sunk to 372.4 V -> 0209 is a CONSTANT rated-max (96 x
//   4.168 V), NOT live pack, exactly as predicted. SERIES COUNT PINNED AT 96S BY DIRECT COUNT. ***]
// [CORRECTION 2026-07-28 (s28 ride + s32 charge): the "0209 = rated-max constant" reading just
//   above is WRONG. 0209 word0 = PACK CURRENT (offset ~1562 counts at 0 A, ~0.26 A/count); the fit
//   1562 + 3.84*I holds OPPOSITE-SIGN across s28 discharge (n=7) AND s32 charge (n=3). The
//   "400106 = 96 x 4.168" was an IDLE-TRAP coincidence: at I~=0, word0 0x061A concatenated with
//   byte2 0xEA reads as 0x061AEA=400106. 96S is UNAFFECTED - it rests on the DIRECT 0205=96-cell
//   COUNT, never on 0209. "Constant != understood" strikes again: two idle sweeps hid a live field.]
// [VSC 0208 REFUTED as pack current 2026-07-28] Do NOT confuse the RESS 0209 pack-current DID
//   above with VSC (0x7E4) DID 0208: 0208 is NOT pack current - r=-0.06 over the full -161..+27 A
//   swing (s28), pinned through a 40 A swing (s31), r=-0.08 (s35). s32's r=-0.544 is a narrow-
//   range monotonic artifact, far weaker than s28's decisive full-swing -0.06. Its byte0 is a
//   binary lateral-activity flag (b0 vs acc_lat r=0.93 s28), byte4 a rolling counter - none
//   track current. The prior 'CONFIRMED-with-caveat' (s13/s16 r~0.9) rested on small-range
//   co-trends, now exposed. The genuine live pack-current DID is RESS 0209 (0x7E6) - a DIFFERENT
//   module. [CANDIDATE] VSC 0205 byte0 = throttle: b0 ~= 2.55x throttle%, b0=0 at 0 throttle
//   (s28 n=14, single-session fit; s32/s33/s34 only re-held the b0=0 zero-anchor) - needs a
//   MOVING throttle sweep at >=2 depths to promote.
// --- SUPERSEDED HISTORICAL DECODE (kept as the research record; do NOT wire) ------
// [RESOLVED] 0x182 is three 16-bit COUNTERS: D1:D2, D3:D4, D5:D6, with D1/D3/D5 as
//   slowly-incrementing high bytes and D2/D4/D6 as fast low bytes.
//   IT LOOKED LIKE MIN/AVG/MAX CELL VOLTAGE and the case was seductive: three
//   channels offset 2-3 counts apart, all sagging under load, spread widening as
//   load increased - exactly cell-imbalance behaviour. [THIS WAS RIGHT - see UPDATE.]
//   WHAT KILLED IT [ERRONEOUSLY]: if they were cell voltages, pack_raw/cell_raw would
//   be constant. It is 0.54 (idle 97 %), 0.56 (load), 6.3 (charging), 12.5 (100 % SoC).
//   The cause was read as WRAPAROUND - but that ratio jump is the pack word's low byte
//   AND the cell word's low byte each crossing a 256 boundary at different SoC, not a
//   counter. Voltages do not wrap; NEITHER of these did - both are 16-bit values whose
//   HIGH bytes were being dropped.
//   ALSO: their r=+0.63 vs battery bar and r=-0.60 vs speed were SPURIOUS, the
//   monotonic-vs-monotonic trap. (That caution stands and is still good practice.)

// ============================================================================
// LOW-VALUE / STRUCTURAL FRAME CENSUS (completeness pass - accounted, not decoded)
// ============================================================================
// 0x164 = 4-PHASE BATTERY-ENERGY MUX (structure resolved 2026-07-28; promoted to BO_ 356
//   below). D1 = phase selector, the WHOLE byte {0x00,0x20,0x40,0x60} cycling every 4
//   frames. For the three non-zero phases, D2:D3 is a FIXED 16-bit CHANNEL TAG and D4:D5 a
//   16-bit BE value: sel0x20 -> tag 0x0331, sel0x40 -> tag 0x07A2 (0x07A3 seen at idle),
//   sel0x60 -> tag 0x0382. Phase 0x00 carries a ROTATING multi-field payload (its D2:D3 tag
//   changes frame to frame). ch(0x0331) and ch(0x0382) are AFFINE-IDENTICAL (ch60 ~=
//   2.168*ch20 + 11064, r~1.0) = ONE physical energy quantity broadcast in two scales; both
//   high at full SoC, decreasing within a discharge ride. E2E-protected (CRC 100%, D7/D8 =
//   counter/CRC). Still open: absolute units + what phase-0x00's rotating payload carries.
//   Never read D2:D5 without gating on D1.
//   [UPDATE 2026-07-29 — 7-session review] REFRAMED: gate on the D1 selector first, then read D2:D5
//   as ONE WIDE (~24-32-bit BE) COULOMB-COUNTED SoC/ENERGY register in 3 selector-set scales -
//   sel 0x20 r=+0.98 (~676 cts/%), sel 0x40 r=+0.98 (~1631 cts/%), sel 0x60 r=-0.95 (INVERTED =
//   depth-of-discharge/energy-consumed) vs displayed SoC over 7 sessions (SoC 47->100). It
//   DIRECTION-REVERSES: falls within a discharge ride (s57 60379->21005 as SoC 71->22, within-ride
//   r=1.00) and rises within a charge (s32 53686->55519) - disqualifying a monotonic co-trend, and
//   tracks SoC NOT terminal voltage (s28 r_soc=0.96 vs r_pv=0.03; rides through WOT voltage sag).
//   The "fixed channel tags" 0x0331/0x07A2/0x0382 are just the HIGH BYTE of the wide register as it
//   rolls/wraps. Phase 0x00 = a separate low-rate diagnostic parameter-ID sweep (D6 non-zero only
//   in phase 0x00). Absolute units (Ah vs Wh vs raw) still UNPINNED - needs a clean full
//   charge/discharge with known Ah throughput. [HIGH structure; units open.]
// 0x184 = mostly-static status/config; D1:D2 slow session value; D5 toggles 0x20/0x30
//   (the USB red-herring). BUT D5 bit5-clear latch (0x20->0x10) + D6 F0->F1->F2 staircase
//   are TC/limiter-intervention candidates under review - see the RIDE 1 / RIDE 3
//   sections of docs/livewire_s2_CAN_speculation.md (do NOT treat as flat "low info").
//   [UPDATE 2026-07-29] D1 = candidate coarse pack-thermal/derate LEVEL (r=+0.93 vs 0x183 pack
//   temps, survives the s54 cool-discharge disconfirmer); D4 bit0 = candidate readiness/power-not-
//   limited flag - see the CANDIDATE notes in the PROPULSION_STATUS_184 (BO_ 388) block above.
// 0x182 = CELL VOLTAGE min/max/avg (RESOLVED - see the CELL_VOLTAGE_182 block above):
//   D1:D2 = min cell mV, D3:D4 = max cell mV, D5:D6 = avg cell mV, ~96S pack. The old
//   "three 16-bit counters" reading here was the low-byte-of-16-bit trap (see that block).
// 0x186 D2 = NET HV ENERGY METER, ~1 Wh/count [UPDATE 2026-07-27, ride1, verified
//   MEDIUM]. It is BIDIRECTIONAL: three decrements observed, all inside genuine
//   regen/decel windows, times reproduce to the ms. ride1 integral of 0x181 V*I =
//   26.97 Wh vs D2 net +27 counts (6->33) over the run. Per-interval rates imply
//   18-54 kW during the pull (<=63 rated), -4.5/-9 kW regen, ~150 W idle. Resets to
//   0 and clamps while charging. So: NET Wh discharged since ignition-on / last charge.
//   *** RETRACTS "usage/distance accumulator" (rate-per-odometer varies 20x across
//   contexts) AND "monotonic counter" (it decrements). Two earlier sub-claims were
//   REFUTED in verification: it does NOT persist across ignition cycles (every reboot
//   zeroes it - the "persisted 47/67/80" were hex misreads of decimal 71/103/128), and
//   its V*I-integral agreement does NOT "certify" the 0x181 decode (that match was not
//   independently reproducible). Scale ~1 Wh/count is +/-20%; occasional +5..+9 batch
//   reconciliation while stationary is unexplained. [STRONG structure, scale unpinned].
//   [UPDATE 2026-07-29] WIDENED: D1:D2 is now read as a 16-bit BE TRIP-ENERGY-CONSUMED word (this
//   D2 is its low byte) and D3:D4 = PACK ENERGY REMAINING (~103 Wh/SoC%, full ~10.3 kWh) - see the
//   HV_ENERGY_186 (BO_ 390) block, which retires the old D3/D4 "OPEN" flags.
// 0x33C / 0x3CE = periodic HEARTBEAT frames: D1 toggles 0x40/0x50 on a fixed ~5%
//   cadence regardless of vehicle state (the rear-brake red-herring). Timekeeping /
//   liveness, not signals.
// 0x188 / 0x189 = TELLTALE + BACKLIGHT AGGREGATION (messy, blink-modulated). Best
//   handle found: 0x188 D4 takes lamp-TYPE-dependent values (~73/74 left turn,
//   ~75/76 right turn, ~80/81 high beam; constant at idle) and 0x189 D3 shifts with
//   high beam - so the cluster packs "which telltales are lit" here, but as a
//   blink-averaged aggregate, not a clean per-lamp bitfield. Use the dedicated lamp
//   signals (0x131 turn, 0x152 high beam) instead; treat 0x188/0x189 as derived.
// 0x128 (296) = SPARSE E2E STATUS FRAME [characterized 2026-07-28] - NOT a live signal.
//   ~0.2 Hz, bursty; header 0x2710 @ D1:D2. The persistent two-state byte is D6 (01/02 in
//   EVERY session incl. s28/s31/s32/s33/s34/s35 - NOT D5, correcting the earlier "D5 2-state"
//   note; D5 is a fixed 0x10 header byte at rest). D3/D4/D5 stay fixed 00/00/10 at rest and
//   in the s31 ride + charge sessions, but POPULATE (D3->0x12/0x13, D4 = 52 distinct values,
//   D5->0x30) ONLY under the s28 stop-and-go city ride - unattributed, too sparse to correlate
//   (single-session, collinear with the s28 decel cluster 0x1A6/0x189/0x133). D7/D8 = E2E
//   alive-counter/CRC (0x128 is already in the PROTECTED-IDs list, line 41; the CRC oracle
//   re-verified 169/169 across s28/s31/s32 - a RE-confirmation, not a first characterization).
//   So: near-inert except under s28 city-ride load; live-but-sparse and unattributed.
//   [CAVEAT 2026-07-29, s57 - PARTIALLY RETRACTS the "NOT a live signal" call above]: on the
//   long s57 ride D3/D4 are demonstrably LIVE, moving-gated propulsion payload (candidate):
//     D4 = zero at standstill (mean 0.0) vs 81.8 moving (range 0-208, 14 values), r=0.70 vs
//          regen (-0.48 vs brake);  D3 = zero at standstill vs 9.1 moving (range 0-19), r=0.75
//          vs regen. Passes the zero-at-standstill + physically-sensible guard (0x128 is a
//     propulsion-cluster frame), but SPARSE (n=74) and single-session -> CANDIDATE, not
//     attributed, and NOT enough to fully overturn the frame-catalog "inert" entry. Likely a
//     propulsion/decel-state level; needs a dedicated capture with varied regen/decel. D5/D6
//     remain 2-state status bits; D7/D8 confirm 0x128 IS E2E-protected.
//   [UPDATE 2026-07-29] PROMOTED to BO_ 296 PROPULSION_ABS_128: D6 = FRONT-BRAKE-APPLIED flag
//     (0x01 off / 0x02 on, thresholded on 0x324, r=0.81..0.91 x6 sessions); D3/D4/D5 kept as the
//     CANDIDATE hard-decel/regen-control block above. See that BO_ block for the full evidence.
// STATUS/FLAG frames, near-constant, activate in specific states (accounted, meaning
//   thin): 0x136 (2-state bytes; old brake guess, NOT brake),
//   0x138 (D2=0x40 else 0), 0x1C7 (mostly 0, a few state flags), 0x338.
// [CONFIRMED 2026-07-30, ultracode round] 0x1C9 = structured CONSTANT 3-phase MUX, NOT a
//   live signal: D3 = whole-byte selector cycling {0x00,0x6A,0x80}; per-phase payload is
//   BYTE-IDENTICAL across 8 regimes incl. both fault captures (sel 0x00->all-0; 0x6A->D2=0x18;
//   0x80->D5=0x3F,D6=0xE0; D1=D4=0x00 always). E2E-protected (D7 counter/D8 CRC, 100% pass).
//   The ONLY regime-dependent behaviour is a heartbeat RATE shift. Corrects the old
//   "0x1C9 mostly 0, a few state flags" characterization.
//   0x392 = TCU CELLULAR/NETWORK frame - see its own block below (NOT a boot config).
// [CONFIRMED 2026-07-30, ultracode round] 0x35A (858) = pure E2E LIVENESS BEACON, no decodable
//   payload: D1-D6 constant 00 00 00 00 02 00 in every capture; only D7 (6-bit alive counter,
//   +1/frame) and D8 (CRC-8/J1850) change; CRC 100%. Sparse/intermittent (1 frame in 915k rows
//   of s57), NOT a steady 1 Hz beacon.
// [NEW 2026-07-30, ultracode round] 0x180 (384) D2 = BOOT STATE-MACHINE: one-shot power-up
//   sequence 0->2->1->0 (clean in ignition.csv; re-shown on re-power in faulted_IMoff_restarted).
//   At RUNTIME it degrades to a bare 0<->1 every-frame liveness toggle with value 2 entirely
//   absent (s57 16/16) - so '2' is a sub-second BOOT artifact, NOT a runtime power/limp state.
//   Retracts any "0x180 D2=0x02 = degraded/fault" reading (it appears in clean ignition captures).
// RESERVED / EMPTY (allocated but unused on the S2): 0x3CA / 0x3CF read all-zero;
//   0x328 (00 FF F0 ..) and 0x3CC (.. FF FE FE) are sentinel-filled - future / other-
//   variant placeholders, not signals to hunt.
// 0x394 = GPS POSITION candidate [TENTATIVE 2026-07-27b - NO LONGER "reserved/empty"].
//   All 8 bytes 0x00 in all 57 captures (no counter/CRC), AND it is the ID-neighbor of
//   the TCU network frame 0x392. Shape is consistent with a GPS lat/lon frame (two 32-bit
//   coords) that never populated. [RESOLVED 2026-07-27] GPS is NOT distributed on the
//   secondary bus as decoded position: a positive UDS search found the TCU (0x7D4) returns
//   an absolute GPS fix on its own DIDs (see docs/livewire_s2_CAN_uds_data_map.md), i.e.
//   position is read point-to-point via UDS, not broadcast. So 0x394 is best read as a
//   reserved/unpopulated slot, not a live position frame - the "capture outside for a fix"
//   test is no longer needed to answer "is GPS on secondary" (answer: no). Leaving the
//   frame documented as all-zero for provenance; it may still be a TCU-local reserved slot.
//   [UDS CROSS-REF 2026-07-28] TCU DID 0200 is now proven LIVE position (continuous multi-
//   session track across the burst: 3 park clusters + 2 in-ride advances, 2.23 km and 1.63 km
//   relocations), refreshing on a ~5 min cadence (4 distinct fixes over 682 s in s28). This
//   reinforces that decoded position is UDS-only and slow-refresh, NOT broadcast per-second
//   on 0x394 (supersedes the "stored GPS fix" wording).
//
// LEFTOVER-BYTE ATTRIBUTION (timeline/action-sequence pass) - partial decodes:
//   0x124 D3 = FRONT-wheel motion indicator (r=0.92 vs 0x326 front, low-res 0-2);
//     0x124 D4 = combined wheel-motion metric (r~0.65 vs BOTH wheels, 16 distinct).
//   0x131 D2 = lighting/telltale byte: 0x1_ base -> 0x2_ high-nibble when HIGH BEAM
//     is on (no change for turn signals). Low nibble blinks. Use 0x152 D3 for beam.
//   0x260 D3 = MODE+STATE composite: mode-linked when powered (Sport 26 / Street 22 /
//     Eco 22 / Rain 24 / CustA 52 / CustB 52 - custom modes hi-nibble 5), low nibble
//     goes 6 when OFF. Another way to read mode; see 0x134 table.
//   0x261 / 0x262 = BOOT-CONFIG frames: populate 0xFF->values at boot then hold
//     CONSTANT at runtime (0x261=D0/55/23.., 0x262=..28/D0). NOT runtime enums - their
//     "many values" in a capture union are just the boot transient. Like 0x392.
//   0x322 D2 = ROLL/LEAN-ANGLE INTEGRATOR [RETRACTED "POWER STATE 0xE7" 2026-07-29] - a mod-256
//     wrapping integral of roll rate (d/dt vs 0x126 gyro_roll r=+0.58..0.70, 4 rides). See the
//     DRIVE_STATE_322 (BO_ 802) block.
//   0x161 D6 = [TENTATIVE] regen/energy-flow flag: 0x74 during regen, 0x04/0x00
//     otherwise (mean 116 regen vs 76 accel in the 75mph run). Weak; within the motor
//     frame so an energy-direction hint, not a magnitude.
//   0x163 D5 (0-4) and D6 (0-190) = NOT power: zero correlation with motor load /
//     battery bar and no regen-vs-accel split. Counters / status within the battery
//     frame, not analog channels.
//
// ============================================================================
// ROUND-4 PROMOTED FRAMES (2026-07-28) - previously undocumented IDs, now decoded
//   and CONFIRMED by cross-capture verification (each empirically re-checked). See
//   docs/livewire_s2_CAN_notes.md round-4 ledger for the full census context.
// ============================================================================
// ---- 0x137 (311) : IGNITION / AUTH PULSE -----------------------------------
BO_ 311 IGNITION_AUTH_137: 8 BCM
 SG_ auth_pulse : 7|8@0+ (1,0) [0|255] "" Vector__XXX

// [CONFIRMED 2026-07-28] Appears ONLY in the startup/ignition captures (ignition,
//   startup_nofob, newcap_9); ABSENT from all ~59 idle/ride captures. D1 = a 3-value
//   pulse enum {0x00, 0x90, 0xA0} that interleaves with the 0x1C3/0x1C5 boot step
//   counter -> an ignition/keyless-auth handshake byte, not a running signal. Non-E2E.
//   (Kills the old "0x136/0x137 = brake" guess: front brake is 0x15A, rear is 0x133 D4.)
// ---- 0x164 (356) : BATTERY-ENERGY 4-PHASE MUX ------------------------------
BO_ 356 BATTERY_ENERGY_MUX_164: 8 Vector__XXX
 SG_ energy_mux_sel : 7|8@0+ (1,0) [0|96] "" Vector__XXX

// Structure fully documented in the 0x164 prose block above. energy_mux_sel = D1 phase
//   selector {0x00,0x20,0x40,0x60}; per-phase D2:D3 channel tag + D4:D5 value. E2E (D7/D8
//   = counter/CRC). ch(0x0331)==affine==ch(0x0382): one energy quantity in two scales.
// [UPDATE 2026-07-29] D2:D5 (gated on the D1 selector) = a WIDE coulomb-counted SoC/ENERGY register
//   in 3 scales (sel 0x20/0x40 positive ~676/1631 cts/%, sel 0x60 INVERTED DoD; direction-reverses
//   charge vs discharge, tracks SoC not voltage, 7 sessions); the "channel tags" are the register's
//   rolling high bytes. Units unpinned. Left as prose (not a wired SG_) because the value is
//   selector-gated - see the reframed 0x164 census block above; keep gating on D1 before any read.
// ---- 0x188 (392) : LAMP / TELLTALE AGGREGATE -------------------------------
BO_ 392 LAMP_TELLTALE_188: 8 Vector__XXX
 SG_ lamp_telltale : 31|8@0+ (1,0) [0|255] "" Vector__XXX

// [CONFIRMED 2026-07-28] E2E-protected. D4 = active turn/beam/hazard telltale aggregate:
//   left-signal 0x49/0x4A, right-signal 0x4B/0x4C, high-beam 0x50/0x51, hazard 0x55,
//   idle/none 0x5D. Verified against the labelled lamp captures. It is the DASH-SIDE
//   telltale rollup (distinct from the switch/lamp-drive states on 0x131/0x152/0x15A).
// ---- 0x1C3 (451) / 0x1C5 (453) : BOOT STEP COUNTER (mirrored) --------------
BO_ 451 BOOT_STEP_1C3: 8 Vector__XXX
 SG_ boot_step_1c3 : 7|8@0+ (1,0) [0|13] "" Vector__XXX

BO_ 453 BOOT_STEP_1C5: 8 Vector__XXX
 SG_ boot_step_1c5 : 39|8@0+ (1,0) [0|13] "" Vector__XXX

// [CONFIRMED 2026-07-28] A synchronized power-up STEP COUNTER mirrored across two IDs:
//   0x1C3 D1 and 0x1C5 D5 both sweep 0x00..0x0D then wrap, with identical step values;
//   0x1C3 leads 0x1C5 by ~1-2 frames. Present ONLY in the 5 startup captures (3 independent
//   boots); absent from every idle/ride capture. A BCM<->partner boot handshake sequence,
//   non-E2E. (Promotes 0x1C5 out of "dark".)
// ---- 0x304 (772) / 0x320 (800) : EHCU/ABS INIT ANNOUNCEMENT (one-shot) -----
BO_ 772 ABS_INIT_304: 8 Vector__XXX

BO_ 800 ABS_INIT_320: 8 Vector__XXX

// [CONFIRMED 2026-07-28] A one-shot EHCU/ABS init-announcement PAIR, exactly ONE frame each,
//   ONLY in the ABS/brake-init captures (brakes_verification, tcabs_preinit); absent
//   everywhere else. Fixed payloads: 0x304 = [0C 18 00 00 0C 20 00 00], 0x320 = [0C 88 00
//   00 0C 90 00 00] - two mirrored half-words +0x08 apart. No variable field (constant
//   announcement), so no SG_. The 0x0C/18/20/88/90 constants' meaning is still open.
// ---- 0x395 (917) : TCU CLOUD-LINK / ACCOUNT-PAIRING STATUS -----------------
BO_ 917 TCU_PAIRING_395: 8 TCU
 SG_ pairing_status      : 7|24@0+ (1,0) [0|16777215] "" Vector__XXX
 SG_ cellular_signal_395 : 47|8@0+ (1,0) [0|255] "" Vector__XXX
